AUTOSAR XML (schema 00048)
package /AUTOLIV/SoftwareComponents/DIA
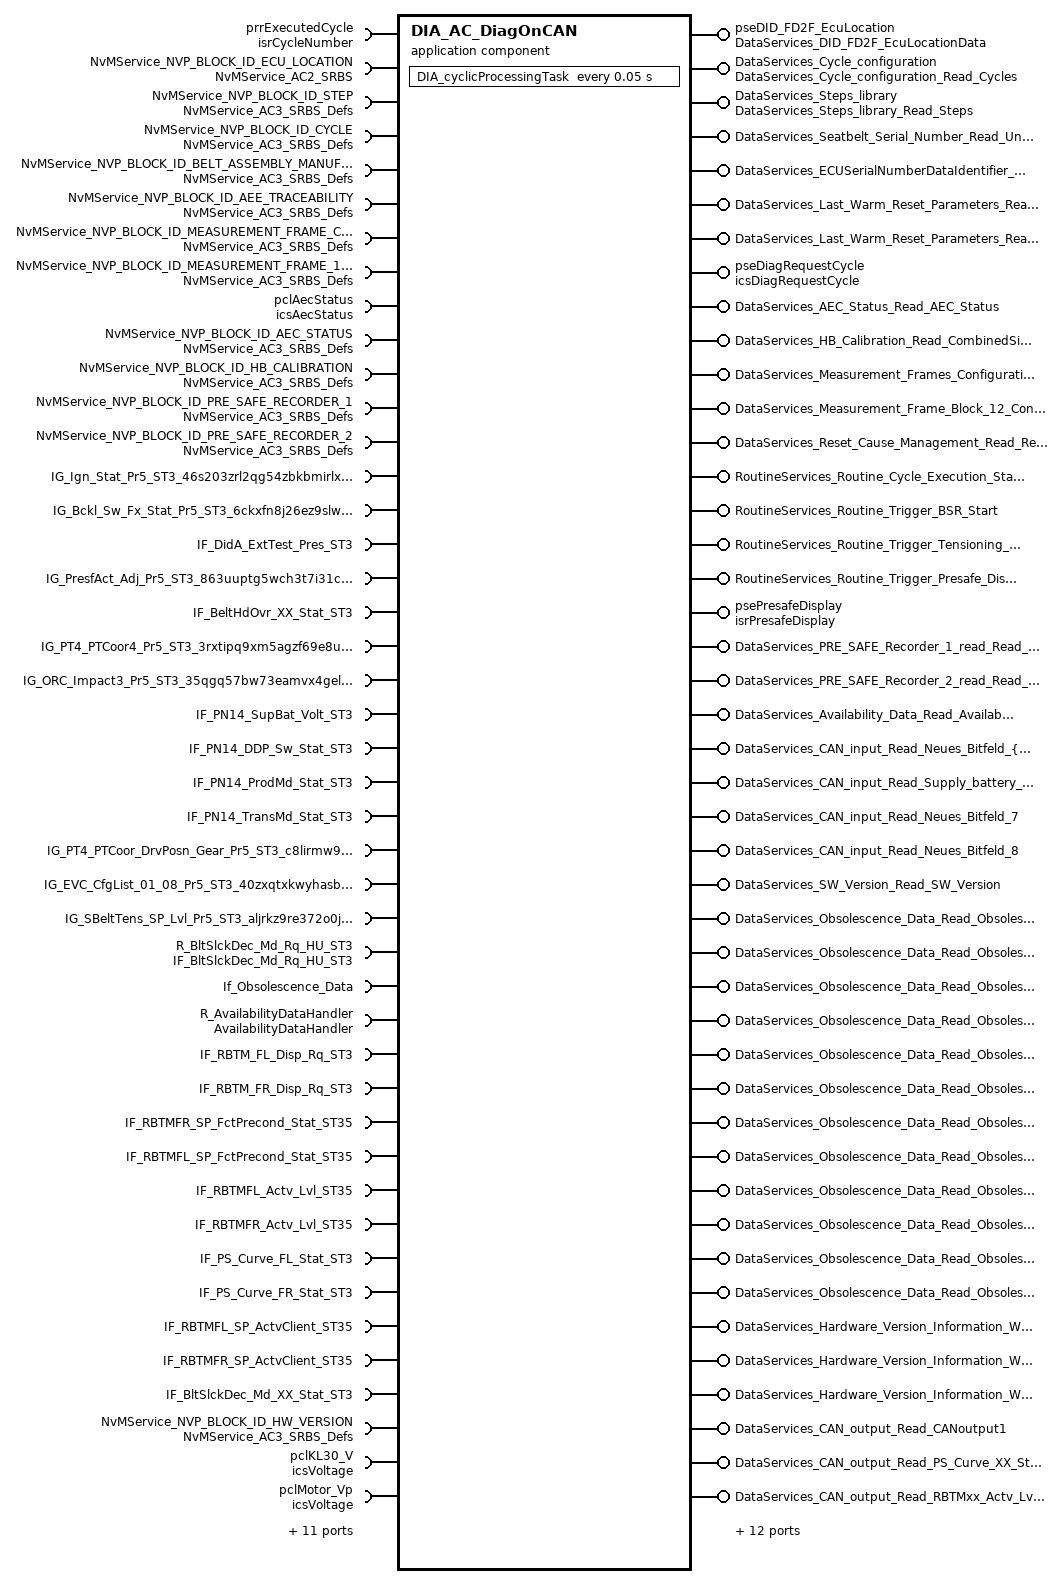
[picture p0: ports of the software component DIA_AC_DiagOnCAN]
  application sw component type DIA_AC_DiagOnCAN
    require port prrExecutedCycle: nonqueued-receiver-com-spec{data-element=u8CycleNumber, init-value=constant-reference=APPLINIT_KU8_CYCLE_NUMBER_NONE}, required-interface=isrCycleNumber
    provide port pseDID_FD2F_EcuLocation: provided-com-specs=[{operation=ReadData, queue-length=1}, {operation=WriteData, queue-length=1}], provided-interface=DataServices_DID_FD2F_EcuLocationData
    require port NvMService_NVP_BLOCK_ID_ECU_LOCATION: required-com-specs=[WriteBlock, SetRamBlockStatus, ReadBlock, GetErrorStatus], required-interface=NvMService_AC2_SRBS
    require port NvMService_NVP_BLOCK_ID_STEP: required-com-specs=[EraseBlock, InvalidateNvBlock, RestoreBlockDefaults, WriteBlock, ReadBlock, SetRamBlockStatus, GetErrorStatus], required-interface=NvMService_AC3_SRBS_Defs
    require port NvMService_NVP_BLOCK_ID_CYCLE: required-com-specs=[EraseBlock, InvalidateNvBlock, RestoreBlockDefaults, WriteBlock, ReadBlock, SetRamBlockStatus, GetErrorStatus], required-interface=NvMService_AC3_SRBS_Defs
    provide port DataServices_Cycle_configuration: provided-com-specs=[{operation=WriteData, queue-length=1}, {operation=ReadData, queue-length=1}], provided-interface=DataServices_Cycle_configuration_Read_Cycles
    provide port DataServices_Steps_library: provided-com-specs=[{operation=WriteData, queue-length=1}, {operation=ReadData, queue-length=1}], provided-interface=DataServices_Steps_library_Read_Steps
    require port NvMService_NVP_BLOCK_ID_BELT_ASSEMBLY_MANUF_DATE_AND_SN: required-com-specs=[EraseBlock, InvalidateNvBlock, RestoreBlockDefaults, WriteBlock, ReadBlock, SetRamBlockStatus, GetErrorStatus], required-interface=NvMService_AC3_SRBS_Defs
    require port NvMService_NVP_BLOCK_ID_AEE_TRACEABILITY: required-com-specs=[EraseBlock, InvalidateNvBlock, RestoreBlockDefaults, WriteBlock, ReadBlock, SetRamBlockStatus, GetErrorStatus], required-interface=NvMService_AC3_SRBS_Defs
    4 x provide port:
      DataServices_Seatbelt_Serial_Number_Read_Unique_Seatbelt_Serialnumber: provided-interface=DataServices_Seatbelt_Serial_Number_Read_Unique_Seatbelt_Serialnumber
        provided-com-specs:
          operation=WriteData, queue-length=1
          operation=ConditionCheckRead, queue-length=1
          operation=ReadData, queue-length=1
      DataServices_ECUSerialNumberDataIdentifier_Read_ECU_Serial_Number: provided-interface=DataServices_ECUSerialNumberDataIdentifier_Read_ECU_Serial_Number
        provided-com-specs:
          operation=ConditionCheckRead, queue-length=1
          operation=ReadDataLength, queue-length=1
          operation=ReadData, queue-length=1
      DataServices_Last_Warm_Reset_Parameters_Read_Last_Detected_Warm_Reset_Cause: provided-com-specs=[{operation=ConditionCheckRead, queue-length=1}, {operation=ReadData, queue-length=1}], provided-interface=DataServices_Last_Warm_Reset_Parameters_Read_Last_Detected_Warm_Reset_Cause
      DataServices_Last_Warm_Reset_Parameters_Read_Reset_Cause_Counter: provided-com-specs=[{operation=ConditionCheckRead, queue-length=1}, {operation=ReadData, queue-length=1}], provided-interface=DataServices_Last_Warm_Reset_Parameters_Read_Reset_Cause_Counter
    require port NvMService_NVP_BLOCK_ID_MEASUREMENT_FRAME_CONFIG: required-com-specs=[EraseBlock, InvalidateNvBlock, RestoreBlockDefaults, WriteBlock, ReadBlock, SetRamBlockStatus, GetErrorStatus], required-interface=NvMService_AC3_SRBS_Defs
    require port NvMService_NVP_BLOCK_ID_MEASUREMENT_FRAME_12_CONFIG: required-com-specs=[EraseBlock, InvalidateNvBlock, RestoreBlockDefaults, WriteBlock, ReadBlock, SetRamBlockStatus, GetErrorStatus], required-interface=NvMService_AC3_SRBS_Defs
    require port pclAecStatus: required-interface=icsAecStatus
      required-com-specs:
        SetAecEvent
        GetNumberOfImplementedAec
        GetAecStatus
        GetAecQualificationCount
        GetAecNvpBlockRecordingStatus
        GetAecGroupsStatus
        GetAecDeskillThrs
    6 x provide port:
      pseDiagRequestCycle: provided-com-specs=[{operation=GetDiagRequestCycle, queue-length=1}, {operation=ClearDiagRequestCycle, queue-length=1}], provided-interface=icsDiagRequestCycle
      DataServices_AEC_Status_Read_AEC_Status: provided-interface=DataServices_AEC_Status_Read_AEC_Status
        provided-com-specs:
          operation=ConditionCheckRead, queue-length=1
          operation=ReadDataLength, queue-length=1
          operation=ReadData, queue-length=1
      DataServices_HB_Calibration_Read_CombinedSignal: provided-interface=DataServices_HB_Calibration_Read_CombinedSignal
        provided-com-specs:
          operation=WriteData, queue-length=1
          operation=ConditionCheckRead, queue-length=1
          operation=ReadData, queue-length=1
      DataServices_Measurement_Frames_Configuration_Read_CombinedSignal: provided-interface=DataServices_Measurement_Frames_Configuration_Read_CombinedSignal
        provided-com-specs:
          operation=WriteData, queue-length=1
          operation=ConditionCheckRead, queue-length=1
          operation=ReadData, queue-length=1
      DataServices_Measurement_Frame_Block_12_Config_Read_CombinedSignal: provided-interface=DataServices_Measurement_Frame_Block_12_Config_Read_CombinedSignal
        provided-com-specs:
          operation=WriteData, queue-length=1
          operation=ConditionCheckRead, queue-length=1
          operation=ReadData, queue-length=1
      DataServices_Reset_Cause_Management_Read_Reset_Cause: provided-com-specs=[{operation=ConditionCheckRead, queue-length=1}, {operation=ReadData, queue-length=1}], provided-interface=DataServices_Reset_Cause_Management_Read_Reset_Cause
    require port NvMService_NVP_BLOCK_ID_AEC_STATUS: required-com-specs=[EraseBlock, InvalidateNvBlock, RestoreBlockDefaults, WriteBlock, ReadBlock, SetRamBlockStatus, GetErrorStatus], required-interface=NvMService_AC3_SRBS_Defs
    require port NvMService_NVP_BLOCK_ID_HB_CALIBRATION: required-com-specs=[EraseBlock, InvalidateNvBlock, RestoreBlockDefaults, WriteBlock, ReadBlock, SetRamBlockStatus, GetErrorStatus], required-interface=NvMService_AC3_SRBS_Defs
    8 x provide port:
      RoutineServices_Routine_Cycle_Execution_Start: provided-interface=RoutineServices_Routine_Cycle_Execution_Start
        provided-com-specs:
          operation=RequestResults, queue-length=1
          operation=Stop, queue-length=1
          operation=Start, queue-length=1
      RoutineServices_Routine_Trigger_BSR_Start: provided-interface=RoutineServices_Routine_Trigger_BSR_Start
        provided-com-specs:
          operation=RequestResults, queue-length=1
          operation=Stop, queue-length=1
          operation=Start, queue-length=1
      RoutineServices_Routine_Trigger_Tensioning_Cycle_Start: provided-interface=RoutineServices_Routine_Trigger_Tensioning_Cycle_Start
        provided-com-specs:
          operation=RequestResults, queue-length=1
          operation=Stop, queue-length=1
          operation=Start, queue-length=1
      RoutineServices_Routine_Trigger_Presafe_Display_Request_Start: provided-interface=RoutineServices_Routine_Trigger_Presafe_Display_Request_Start
        provided-com-specs:
          operation=RequestResults, queue-length=1
          operation=Stop, queue-length=1
          operation=Start, queue-length=1
      psePresafeDisplay: nonqueued-sender-com-spec{data-element=b8TriggerPreSafeRequestStatus, init-value=constant-reference=APPLINIT_KB8_BOOLEAN_FALSE}, provided-interface=isrPresafeDisplay
      DataServices_PRE_SAFE_Recorder_1_read_Read_CombinedDataElement: provided-interface=DataServices_PRE_SAFE_Recorder_1_read_Read_CombinedDataElement
        provided-com-specs:
          operation=WriteData, queue-length=1
          operation=ConditionCheckRead, queue-length=1
          operation=ReadDataLength, queue-length=1
          operation=ReadData, queue-length=1
      DataServices_PRE_SAFE_Recorder_2_read_Read_CombinedDataElement: provided-interface=DataServices_PRE_SAFE_Recorder_2_read_Read_CombinedDataElement
        provided-com-specs:
          operation=WriteData, queue-length=1
          operation=ConditionCheckRead, queue-length=1
          operation=ReadDataLength, queue-length=1
          operation=ReadData, queue-length=1
      DataServices_Availability_Data_Read_Availability_Data_PRE_SAFE_haptic_warning: provided-com-specs=[{operation=ConditionCheckRead, queue-length=1}, {operation=ReadData, queue-length=1}], provided-interface=DataServices_Availability_Data_Read_Availability_Data_PRE_SAFE_haptic_warning
    16 x require port:
      NvMService_NVP_BLOCK_ID_PRE_SAFE_RECORDER_1: required-com-specs=[EraseBlock, InvalidateNvBlock, RestoreBlockDefaults, WriteBlock, ReadBlock, SetRamBlockStatus, GetErrorStatus], required-interface=NvMService_AC3_SRBS_Defs
      NvMService_NVP_BLOCK_ID_PRE_SAFE_RECORDER_2: required-com-specs=[EraseBlock, InvalidateNvBlock, RestoreBlockDefaults, WriteBlock, ReadBlock, SetRamBlockStatus, GetErrorStatus], required-interface=NvMService_AC3_SRBS_Defs
      IG_Ign_Stat_Pr5_ST3_46s203zrl2qg54zbkbmirlx2b: nonqueued-receiver-com-spec{data-element=Ign_Stat_Pr5_ST3, filter=data-filter-type=ALWAYS, init-value=constant-reference=XDIS_8ptnmozvvqneybwnb1dteqblf}, required-interface=IG_Ign_Stat_Pr5_ST3_46s203zrl2qg54zbkbmirlx2b
      IG_Bckl_Sw_Fx_Stat_Pr5_ST3_6ckxfn8j26ez9slws8s7zuact: nonqueued-receiver-com-spec{data-element=Bckl_Sw_Fx_Stat_Pr5_ST3, filter=data-filter-type=ALWAYS, init-value=constant-reference=XDIS_by5k2ulzqy4hav7734lki195k}, required-interface=IG_Bckl_Sw_Fx_Stat_Pr5_ST3_6ckxfn8j26ez9slws8s7zuact
      IF_DidA_ExtTest_Pres_ST3: nonqueued-receiver-com-spec{data-element=DidA_ExtTest_Pres_ST3, filter=data-filter-type=ALWAYS, init-value=constant-reference=XDIS_f4mtuwvd3r353o80f6rps7w7}, required-interface=IF_DidA_ExtTest_Pres_ST3
      IG_PresfAct_Adj_Pr5_ST3_863uuptg5wch3t7i31c8crpa2: nonqueued-receiver-com-spec{data-element=PresfAct_Adj_Pr5_ST3, filter=data-filter-type=ALWAYS, init-value=constant-reference=XDIS_1lex2znuqx5p6s5yy1dyffpdg}, required-interface=IG_PresfAct_Adj_Pr5_ST3_863uuptg5wch3t7i31c8crpa2
      IF_BeltHdOvr_XX_Stat_ST3: nonqueued-receiver-com-spec{data-element=BeltHdOvr_XX_Stat_ST3, filter=data-filter-type=ALWAYS, init-value=constant-reference=XDIS_9pu33xhskzhvc3a6idhpuk7uh}, required-interface=IF_BeltHdOvr_XX_Stat_ST3
      IG_PT4_PTCoor4_Pr5_ST3_3rxtipq9xm5agzf69e8usehmj: nonqueued-receiver-com-spec{data-element=PT4_PTCoor4_Pr5_ST3, filter=data-filter-type=ALWAYS, init-value=constant-reference=XDIS_9h6oqehaueepowg2tijus0mir}, required-interface=IG_PT4_PTCoor4_Pr5_ST3_3rxtipq9xm5agzf69e8usehmj
      IG_ORC_Impact3_Pr5_ST3_35qgq57bw73eamvx4gelk7iiv: nonqueued-receiver-com-spec{data-element=ORC_Impact3_Pr5_ST3, filter=data-filter-type=ALWAYS, init-value=constant-reference=XDIS_7frhrem3wt9j2oidbosrki6rx}, required-interface=IG_ORC_Impact3_Pr5_ST3_35qgq57bw73eamvx4gelk7iiv
      IF_PN14_SupBat_Volt_ST3: nonqueued-receiver-com-spec{data-element=PN14_SupBat_Volt_ST3, filter=data-filter-type=ALWAYS, init-value=constant-reference=XDIS_9jzhpgyeg4j2n16k3jmfeesjo}, required-interface=IF_PN14_SupBat_Volt_ST3
      IF_PN14_DDP_Sw_Stat_ST3: nonqueued-receiver-com-spec{data-element=PN14_DDP_Sw_Stat_ST3, filter=data-filter-type=ALWAYS, init-value=constant-reference=XDIS_c8apwmaohcx1gxigvciebloy2}, required-interface=IF_PN14_DDP_Sw_Stat_ST3
      IF_PN14_ProdMd_Stat_ST3: nonqueued-receiver-com-spec{data-element=PN14_ProdMd_Stat_ST3, filter=data-filter-type=ALWAYS, init-value=constant-reference=XDIS_4um78o9kgep1cp3dhn51ycc2o}, required-interface=IF_PN14_ProdMd_Stat_ST3
      IF_PN14_TransMd_Stat_ST3: nonqueued-receiver-com-spec{data-element=PN14_TransMd_Stat_ST3, filter=data-filter-type=ALWAYS, init-value=constant-reference=XDIS_18rb2bxx4r5d75figzrcw50gp}, required-interface=IF_PN14_TransMd_Stat_ST3
      IG_PT4_PTCoor_DrvPosn_Gear_Pr5_ST3_c8lirmw9wm5odas0h648yyd4w: nonqueued-receiver-com-spec{data-element=PT4_PTCoor_DrvPosn_Gear_Pr5_ST3, filter=data-filter-type=ALWAYS, init-value=constant-reference=XDIS_8ocy3iwo1ditemd6qwphg7b7i}, required-interface=IG_PT4_PTCoor_DrvPosn_Gear_Pr5_ST3_c8lirmw9wm5odas0h648yyd4w
      IG_EVC_CfgList_01_08_Pr5_ST3_40zxqtxkwyhasb66rr3qexjf2: nonqueued-receiver-com-spec{data-element=EVC_CfgList_01_08_Pr5_ST3, filter=data-filter-type=ALWAYS, init-value=constant-reference=XDIS_7tqm5jy9oba0thvws62i3l28n}, required-interface=IG_EVC_CfgList_01_08_Pr5_ST3_40zxqtxkwyhasb66rr3qexjf2
      IG_SBeltTens_SP_Lvl_Pr5_ST3_aljrkz9re372o0jtum2i5lh8w: nonqueued-receiver-com-spec{data-element=SBeltTens_SP_Lvl_Pr5_ST3, filter=data-filter-type=ALWAYS, init-value=constant-reference=XDIS_4wiqeqoz18rz4k73xcp12oii1}, required-interface=IG_SBeltTens_SP_Lvl_Pr5_ST3_aljrkz9re372o0jtum2i5lh8w
    10 x provide port, all with provided-com-specs=[{operation=ConditionCheckRead, queue-length=1}, {operation=ReadData, queue-length=1}]:
      DataServices_CAN_input_Read_Neues_Bitfeld_{1..6}: provided-interface=DataServices_CAN_input_Read_Neues_Bitfeld_{1..6}
      DataServices_CAN_input_Read_Supply_battery_voltage: provided-interface=DataServices_CAN_input_Read_Supply_battery_voltage
      DataServices_CAN_input_Read_Neues_Bitfeld_7: provided-interface=DataServices_CAN_input_Read_Neues_Bitfeld_7
      DataServices_CAN_input_Read_Neues_Bitfeld_8: provided-interface=DataServices_CAN_input_Read_Neues_Bitfeld_8
      DataServices_SW_Version_Read_SW_Version: provided-interface=DataServices_SW_Version_Read_SW_Version
    require port R_BltSlckDec_Md_Rq_HU_ST3: nonqueued-receiver-com-spec{data-element=BltSlckDec_Md_Rq_HU_ST3, filter=data-filter-type=ALWAYS, init-value=constant-reference=XDIS_1vei4uht6zuq0e57z2qtds6y7}, required-interface=IF_BltSlckDec_Md_Rq_HU_ST3
    12 x provide port, all with provided-com-specs=[{operation=ConditionCheckRead, queue-length=1}, {operation=ReadData, queue-length=1}]:
      DataServices_Obsolescence_Data_Read_Obsolescence_Data_BSR_Current_Value: provided-interface=DataServices_Obsolescence_Data_Read_Obsolescence_Data_BSR_Current_Value
      DataServices_Obsolescence_Data_Read_Obsolescence_Data_BSR_Threshold_Green_to_Yellow: provided-interface=DataServices_Obsolescence_Data_Read_Obsolescence_Data_BSR_Threshold_Green_to_Yellow
      DataServices_Obsolescence_Data_Read_Obsolescence_Data_BSR_Threshold_Yellow_to_Red: provided-interface=DataServices_Obsolescence_Data_Read_Obsolescence_Data_BSR_Threshold_Yellow_to_Red
      DataServices_Obsolescence_Data_Read_Obsolescence_Data_haptic_Warning_Current_Value: provided-interface=DataServices_Obsolescence_Data_Read_Obsolescence_Data_haptic_Warning_Current_Value
      DataServices_Obsolescence_Data_Read_Obsolescence_Data_haptic_Warning_Threshold_Green_to_Yellow: provided-interface=DataServices_Obsolescence_Data_Read_Obsolescence_Data_haptic_Warning_Threshold_Green_to_Yellow
      DataServices_Obsolescence_Data_Read_Obsolescence_Data_haptic_Warning_Threshold_Yellow_to_Red: provided-interface=DataServices_Obsolescence_Data_Read_Obsolescence_Data_haptic_Warning_Threshold_Yellow_to_Red
      DataServices_Obsolescence_Data_Read_Obsolescence_Data_PRE_CRASH_Current_Value: provided-interface=DataServices_Obsolescence_Data_Read_Obsolescence_Data_PRE_CRASH_Current_Value
      DataServices_Obsolescence_Data_Read_Obsolescence_Data_PRE_CRASH_Threshold_Green_to_Yellow: provided-interface=DataServices_Obsolescence_Data_Read_Obsolescence_Data_PRE_CRASH_Threshold_Green_to_Yellow
      DataServices_Obsolescence_Data_Read_Obsolescence_Data_PRE_CRASH_Threshold_Yellow_to_Red: provided-interface=DataServices_Obsolescence_Data_Read_Obsolescence_Data_PRE_CRASH_Threshold_Yellow_to_Red
      DataServices_Obsolescence_Data_Read_Obsolescence_Data_PRE_SAFE_Lvl_4_5_Current_Value: provided-interface=DataServices_Obsolescence_Data_Read_Obsolescence_Data_PRE_SAFE_Lvl_4_5_Current_Value
      DataServices_Obsolescence_Data_Read_Obsolescence_Data_PRE_SAFE_Lvl_4_5_Threshold_Green_to_Yellow: provided-interface=DataServices_Obsolescence_Data_Read_Obsolescence_Data_PRE_SAFE_Lvl_4_5_Threshold_Green_to_Yellow
      DataServices_Obsolescence_Data_Read_Obsolescence_Data_PRE_SAFE_Lvl_4_5_Threshold_Yellow_to_Red: provided-interface=DataServices_Obsolescence_Data_Read_Obsolescence_Data_PRE_SAFE_Lvl_4_5_Threshold_Yellow_to_Red
    require port If_Obsolescence_Data: required-com-specs=[Write_Data, Get_Data], required-interface=If_Obsolescence_Data
    require port R_AvailabilityDataHandler: nonqueued-receiver-com-spec{data-element=AvailabilityDataCategory, filter=data-filter-type=ALWAYS, init-value=0}, required-interface=AvailabilityDataHandler
    provide port DataServices_Hardware_Version_Information_Write_HW_year: server-com-spec{operation=WriteData, queue-length=1}, provided-interface=DataServices_Hardware_Version_Information_Write_HW_year
    provide port DataServices_Hardware_Version_Information_Write_HW_week: server-com-spec{operation=WriteData, queue-length=1}, provided-interface=DataServices_Hardware_Version_Information_Write_HW_week
    provide port DataServices_Hardware_Version_Information_Write_HW_patch_level: server-com-spec{operation=WriteData, queue-length=1}, provided-interface=DataServices_Hardware_Version_Information_Write_HW_patch_level
    11 x require port:
      IF_RBTM_FL_Disp_Rq_ST3: nonqueued-receiver-com-spec{data-element=RBTM_FL_Disp_Rq_ST3, filter=data-filter-type=ALWAYS}, required-interface=IF_RBTM_FL_Disp_Rq_ST3
      IF_RBTM_FR_Disp_Rq_ST3: nonqueued-receiver-com-spec{data-element=RBTM_FR_Disp_Rq_ST3, filter=data-filter-type=ALWAYS}, required-interface=IF_RBTM_FR_Disp_Rq_ST3
      IF_RBTMFR_SP_FctPrecond_Stat_ST35: nonqueued-receiver-com-spec{data-element=RBTMFR_SP_FctPrecond_Stat_ST35, filter=data-filter-type=ALWAYS}, required-interface=IF_RBTMFR_SP_FctPrecond_Stat_ST35
      IF_RBTMFL_SP_FctPrecond_Stat_ST35: nonqueued-receiver-com-spec{data-element=RBTMFL_SP_FctPrecond_Stat_ST35, filter=data-filter-type=ALWAYS}, required-interface=IF_RBTMFL_SP_FctPrecond_Stat_ST35
      IF_RBTMFL_Actv_Lvl_ST35: nonqueued-receiver-com-spec{data-element=RBTMFL_Actv_Lvl_ST35, filter=data-filter-type=ALWAYS}, required-interface=IF_RBTMFL_Actv_Lvl_ST35
      IF_RBTMFR_Actv_Lvl_ST35: nonqueued-receiver-com-spec{data-element=RBTMFR_Actv_Lvl_ST35, filter=data-filter-type=ALWAYS}, required-interface=IF_RBTMFR_Actv_Lvl_ST35
      IF_PS_Curve_FL_Stat_ST3: nonqueued-receiver-com-spec{data-element=PS_Curve_FL_Stat_ST3, filter=data-filter-type=ALWAYS}, required-interface=IF_PS_Curve_FL_Stat_ST3
      IF_PS_Curve_FR_Stat_ST3: nonqueued-receiver-com-spec{data-element=PS_Curve_FR_Stat_ST3, filter=data-filter-type=ALWAYS}, required-interface=IF_PS_Curve_FR_Stat_ST3
      IF_RBTMFL_SP_ActvClient_ST35: nonqueued-receiver-com-spec{data-element=RBTMFL_SP_ActvClient_ST35, filter=data-filter-type=ALWAYS}, required-interface=IF_RBTMFL_SP_ActvClient_ST35
      IF_RBTMFR_SP_ActvClient_ST35: nonqueued-receiver-com-spec{data-element=RBTMFR_SP_ActvClient_ST35, filter=data-filter-type=ALWAYS}, required-interface=IF_RBTMFR_SP_ActvClient_ST35
      IF_BltSlckDec_Md_XX_Stat_ST3: nonqueued-receiver-com-spec{data-element=BltSlckDec_Md_XX_Stat_ST3, filter=data-filter-type=ALWAYS, init-value=3}, required-interface=IF_BltSlckDec_Md_XX_Stat_ST3
    5 x provide port, all with provided-com-specs=[{operation=ConditionCheckRead, queue-length=1}, {operation=ReadData, queue-length=1}]:
      DataServices_CAN_output_Read_CANoutput1: provided-interface=DataServices_CAN_output_Read_CANoutput1
      DataServices_CAN_output_Read_PS_Curve_XX_Stat_ST3: provided-interface=DataServices_CAN_output_Read_PS_Curve_XX_Stat_ST3
      DataServices_CAN_output_Read_RBTMxx_Actv_Lvl_ST35: provided-interface=DataServices_CAN_output_Read_RBTMxx_Actv_Lvl_ST35
      DataServices_CAN_output_Read_RBTMxx_SP_ActvClient_ST35: provided-interface=DataServices_CAN_output_Read_RBTMxx_SP_ActvClient_ST35
      DataServices_CAN_output_Read_RBTMxx_SP_FctPrecond_Stat_ST35: provided-interface=DataServices_CAN_output_Read_RBTMxx_SP_FctPrecond_Stat_ST35
    require port NvMService_NVP_BLOCK_ID_HW_VERSION: required-com-specs=[EraseBlock, InvalidateNvBlock, RestoreBlockDefaults, WriteBlock, ReadBlock, SetRamBlockStatus, GetErrorStatus], required-interface=NvMService_AC3_SRBS_Defs
    4 x provide port, all with provided-com-specs=[{operation=ConditionCheckRead, queue-length=1}, {operation=ReadData, queue-length=1}]:
      DataServices_Internal_ECU_information_Read_ECU_Temperature: provided-interface=DataServices_Internal_ECU_information_Read_ECU_Temperature
      DataServices_Internal_ECU_information_Read_MOTOR_Current: provided-interface=DataServices_Internal_ECU_information_Read_MOTOR_Current
      DataServices_HW_input_Read_Voltage_KL30t: provided-interface=DataServices_HW_input_Read_Voltage_KL30t
      DataServices_HW_input_Read_Voltage_Motor: provided-interface=DataServices_HW_input_Read_Voltage_Motor
    4 x require port:
      pclKL30_V: required-com-specs=[Get_2ms, Get_20ms, Get_10ms, Get_100ms, Get], required-interface=icsVoltage
      pclMotor_Vp: required-com-specs=[Get_2ms, Get_20ms, Get_10ms, Get_100ms, Get], required-interface=icsVoltage
      pclMotor_I: required-com-specs=[Get_mA, Get_LSB, Get_A, ConvertCurrent_mAtoLSB], required-interface=icsCurrent
      pclECUT_T: required-com-specs=[Init, GetFiltered_deg, GetFiltered], required-interface=icsTemperature
    provide port DataServices_Internal_ECU_information_Read_Autosar_System_State_EcuM_State: provided-com-specs=[{operation=ConditionCheckRead, queue-length=1}, {operation=ReadData, queue-length=1}], provided-interface=DataServices_Internal_ECU_information_Read_Autosar_System_State_EcuM_State
    require port EcuM_CurrentMode: mode-switch-receiver-com-spec=currentMode, required-interface=EcuM_CurrentMode
    provide port DataServices_ECU_serial_number_Read_PCBA_Programmed_Part_number: provided-interface=DataServices_ECU_serial_number_Read_PCBA_Programmed_Part_number
      provided-com-specs:
        operation=WriteData, queue-length=1
        operation=ConditionCheckRead, queue-length=1
        operation=ReadData, queue-length=1
    provide port DataServices_ECU_serial_number_Read_ECU_traceability_number: provided-interface=DataServices_ECU_serial_number_Read_ECU_traceability_number
      provided-com-specs:
        operation=WriteData, queue-length=1
        operation=ConditionCheckRead, queue-length=1
        operation=ReadData, queue-length=1
    require port icsResetCause: required-com-specs=[GetResetCause, DetermineResetCause, ConfirmResetCause], required-interface=icsResetCause
    require port DcmDiagnosticSessionControl: mode-switch-receiver-com-spec=DcmDiagnosticSessionControl, required-interface=DcmDiagnosticSessionControl
    require port IF_VehSpd_Disp_ST3: nonqueued-receiver-com-spec{data-element=VehSpd_Disp_ST3, filter=data-filter-type=ALWAYS, init-value=0}, required-interface=IF_VehSpd_Disp_ST3
    provide port RoutineServices_Routine_Check_Reprogramming_Preconditions_Start: server-com-spec{operation=Start, queue-length=1}, provided-interface=RoutineServices_Routine_Check_Reprogramming_Preconditions_Start
    require port prrExtTestPres: required-interface=isrExtTestPres
      required-com-specs:
        data-element=b8ExtTesterPresent, filter=data-filter-type=ALWAYS
        data-element=b8DTCConfirmed, filter=data-filter-type=ALWAYS
    require port prrDTCConfirmed: required-interface=isrExtTestPres
      required-com-specs:
        data-element=b8DTCConfirmed, filter=data-filter-type=ALWAYS, init-value=constant-reference=APPLINIT_KB8_BOOLEAN_FALSE
        data-element=b8ExtTesterPresent, filter=data-filter-type=ALWAYS, init-value=constant-reference=APPLINIT_KB8_BOOLEAN_FALSE
    provide port DataServices_Temperature_Sensor_Calibration_Point_Read_Offset_Point: provided-interface=DataServices_Temperature_Sensor_Calibration_Point_Read_Offset_Point
      provided-com-specs:
        operation=WriteData, queue-length=1
        operation=ConditionCheckRead, queue-length=1
        operation=ReadData, queue-length=1
    require port NvMService_NVP_BLOCK_TEMP_SENSOR_TABLE: required-com-specs=[EraseBlock, InvalidateNvBlock, RestoreBlockDefaults, WriteBlock, ReadBlock, SetRamBlockStatus, GetErrorStatus], required-interface=NvMService_AC3_SRBS_Defs
    provide port DataServices_Velocity_PI_Regulation_Coefficient_Read_Input_Velocity_Coefficient: provided-interface=DataServices_Velocity_PI_Regulation_Coefficient_Read_Input_Velocity_Coefficient
      provided-com-specs:
        operation=WriteData, queue-length=1
        operation=ConditionCheckRead, queue-length=1
        operation=ReadData, queue-length=1
    require port NvMService_NVP_BLOCK_ID_VELOCITY_PID_PARAM: required-com-specs=[EraseBlock, InvalidateNvBlock, RestoreBlockDefaults, WriteBlock, ReadBlock, SetRamBlockStatus, GetErrorStatus], required-interface=NvMService_AC3_SRBS_Defs
    require port NvMService_NVP_BLOCK_ID_PCBA_PPN: required-com-specs=[EraseBlock, InvalidateNvBlock, RestoreBlockDefaults, WriteBlock, ReadBlock, SetRamBlockStatus, GetErrorStatus], required-interface=NvMService_AC3_SRBS_Defs
    behavior DIA_IB_DiagOnCAN: data-type-mapping=[DataTypeMappingSet_PP4G, DataTypeMappings_DEV]
      41 x operation invoked event:
        oie_pseDID_FD2F_EcuLocation_ReadData: start-on-event=DIA_runDidFD2F_EcuLocationRead, operation=pseDID_FD2F_EcuLocation.ReadData
        oie_pseDID_FD2F_EcuLocation_WriteData: start-on-event=DIA_runDidFD2F_EcuLocationWrite, operation=pseDID_FD2F_EcuLocation.WriteData
        OIT_DIA_runDidFD2A_StepsLibraryWrite_DataServices_Steps_library_WriteData: start-on-event=DIA_runDidFD2A_StepsLibraryWrite, operation=DataServices_Steps_library.WriteData
        OIT_DIA_runDidFD2A_StepsLibraryRead_DataServices_Steps_library_ReadData: start-on-event=DIA_runDidFD2A_StepsLibraryRead, operation=DataServices_Steps_library.ReadData
        OIT_DIA_runDidFD10_CycleConfigurationRead_DataServices_Cycle_configuration_ReadData: start-on-event=DIA_runDidFD10_CycleConfigurationRead, operation=DataServices_Cycle_configuration.ReadData
        OIT_DIA_runDidFD10_CycleConfigurationWrite_DataServices_Cycle_configuration_WriteData: start-on-event=DIA_runDidFD10_CycleConfigurationWrite, operation=DataServices_Cycle_configuration.WriteData
        OIT_DIA_runDid0340_UniqueSeatbeltSerialNumberConditionCheckRead_DataServices_Seatbelt_Serial_Number_Read_Unique_SeatbeltFBF9722C: start-on-event=DIA_runDid0340_UniqueSeatbeltSerialNumberConditionCheckRead, operation=DataServices_Seatbelt_Serial_Number_Read_Unique_Seatbelt_Serialnumber.ConditionCheckRead
        OIT_DIA_runDid0340_UniqueSeatbeltSerialNumberRead_DataServices_Seatbelt_Serial_Number_Read_Unique_Seatbelt_Serialnumber_ReadData: start-on-event=DIA_runDid0340_UniqueSeatbeltSerialNumberRead, operation=DataServices_Seatbelt_Serial_Number_Read_Unique_Seatbelt_Serialnumber.ReadData
        OIT_DIA_runDid0340_UniqueSeatbeltSerialNumberWrite_DataServices_Seatbelt_Serial_Number_Read_Unique_Seatbelt_Serialnumber2E96F11D: start-on-event=DIA_runDid0340_UniqueSeatbeltSerialNumberWrite, operation=DataServices_Seatbelt_Serial_Number_Read_Unique_Seatbelt_Serialnumber.WriteData
        OIT_DIA_runDidF18C_EcuSerialNumberConditionCheckRead_DataServices_ECUSerialNumberDataIdentifier_Read_ECU_Serial_Number_C2B16EED8: start-on-event=DIA_runDidF18C_EcuSerialNumberConditionCheckRead, operation=DataServices_ECUSerialNumberDataIdentifier_Read_ECU_Serial_Number.ConditionCheckRead
        OIT_DIA_runDidF18C_EcuSerialNumberRead_DataServices_ECUSerialNumberDataIdentifier_Read_ECU_Serial_Number_ReadData: start-on-event=DIA_runDidF18C_EcuSerialNumberRead, operation=DataServices_ECUSerialNumberDataIdentifier_Read_ECU_Serial_Number.ReadData
        OIT_DIA_runDidF18C_EcuSerialNumberReadDataLength_DataServices_ECUSerialNumberDataIdentifier_Read_ECU_Serial_Number_ReadDB340CCB8: start-on-event=DIA_runDidF18C_EcuSerialNumberReadDataLength, operation=DataServices_ECUSerialNumberDataIdentifier_Read_ECU_Serial_Number.ReadDataLength
        OIT_DIA_runDidFD09_LastWarmResetConditionCheckRead_ResetCauseCounter_DataServices_Last_Warm_Reset_Parameters_Read_Reset_52475C36: start-on-event=DIA_runDidFD09_LastWarmResetConditionCheckRead_ResetCauseCounter, operation=DataServices_Last_Warm_Reset_Parameters_Read_Reset_Cause_Counter.ConditionCheckRead
        OIT_DIA_runDidFD09_LastWarmReseConditionChecktRead_LastDetectedWarmResetCause_DataServices_Last_Warm_Reset_Parameters_Re84DF461B: start-on-event=DIA_runDidFD09_LastWarmReseConditionChecktRead_LastDetectedWarmResetCause, operation=DataServices_Last_Warm_Reset_Parameters_Read_Last_Detected_Warm_Reset_Cause.ConditionCheckRead
        OIT_DIA_runDidFD09_LastWarmResetRead_LastDetectedWarmResetCause_DataServices_Last_Warm_Reset_Parameters_Read_Last_DetectB87375AF: start-on-event=DIA_runDidFD09_LastWarmResetRead_LastDetectedWarmResetCause, operation=DataServices_Last_Warm_Reset_Parameters_Read_Last_Detected_Warm_Reset_Cause.ReadData
        OIT_DIA_runDidFD09_LastWarmResetRead_ResetCauseCounter_DataServices_Last_Warm_Reset_Parameters_Read_Reset_Cause_Counter_ReadData: start-on-event=DIA_runDidFD09_LastWarmResetRead_ResetCauseCounter, operation=DataServices_Last_Warm_Reset_Parameters_Read_Reset_Cause_Counter.ReadData
        OIT_DIA_runGetDiagRequestCycle_pseDiagRequestCycle_GetDiagRequestCycle: start-on-event=DIA_runGetDiagRequestCycle, operation=pseDiagRequestCycle.GetDiagRequestCycle
        OIT_DIA_runClearDiagRequestCycle_pseDiagRequestCycle_ClearDiagRequestCycle: start-on-event=DIA_runClearDiagRequestCycle, operation=pseDiagRequestCycle.ClearDiagRequestCycle
        OIT_DIA_runDidFEFF_MeasuruementFrameConfigurationRead_DataServices_Measurement_Frames_Configuration_Read_CombinedSignal_ReadData: start-on-event=DIA_runDidFEFF_MeasuruementFrameConfigurationRead, operation=DataServices_Measurement_Frames_Configuration_Read_CombinedSignal.ReadData
        OIT_DIA_runDidFEFF_MeasuruementFrameConfigurationWrite_DataServices_Measurement_Frames_Configuration_Read_CombinedSignal10D7FD8D: start-on-event=DIA_runDidFEFF_MeasuruementFrameConfigurationWrite, operation=DataServices_Measurement_Frames_Configuration_Read_CombinedSignal.WriteData
        OIT_DIA_runDidFEFF_MeasuruementFrameConfigurationConditionCheckRead_DataServices_Measurement_Frames_Configuration_Read_C87A3B1E5: start-on-event=DIA_runDidFEFF_MeasuruementFrameConfigurationConditionCheckRead, operation=DataServices_Measurement_Frames_Configuration_Read_CombinedSignal.ConditionCheckRead
        OIT_DIA_runDidFD31_HBCalibrationRead_DataServices_HB_Calibration_Read_CombinedSignal_ReadData: start-on-event=DIA_runDidFD31_HBCalibrationRead, operation=DataServices_HB_Calibration_Read_CombinedSignal.ReadData
        OIT_DIA_runDidFD31_HBCalibrationWrite_DataServices_HB_Calibration_Read_CombinedSignal_WriteData: start-on-event=DIA_runDidFD31_HBCalibrationWrite, operation=DataServices_HB_Calibration_Read_CombinedSignal.WriteData
        OIT_DIA_runDidFD31_HBCalibrationWriteConditionCheckRead_DataServices_HB_Calibration_Read_CombinedSignal_ConditionCheckRead: start-on-event=DIA_runDidFD31_HBCalibrationWriteConditionCheckRead, operation=DataServices_HB_Calibration_Read_CombinedSignal.ConditionCheckRead
        OIT_DIA_runDidFDFF_MeasurementFrameBlock12ConfigConditionCheckRead_DataServices_Measurement_Frame_Block_12_Config_Read_C10E2BBE6: start-on-event=DIA_runDidFDFF_MeasurementFrameBlock12ConfigConditionCheckRead, operation=DataServices_Measurement_Frame_Block_12_Config_Read_CombinedSignal.ConditionCheckRead
        OIT_DIA_runDidFDFF_MeasurementFrameBlock12ConfigRead_DataServices_Measurement_Frame_Block_12_Config_Read_CombinedSignal_ReadData: start-on-event=DIA_runDidFDFF_MeasurementFrameBlock12ConfigRead, operation=DataServices_Measurement_Frame_Block_12_Config_Read_CombinedSignal.ReadData
        OIT_DIA_runDidFDFF_MeasurementFrameBlock12ConfigWrite_DataServices_Measurement_Frame_Block_12_Config_Read_CombinedSignalF9DD0DE8: start-on-event=DIA_runDidFDFF_MeasurementFrameBlock12ConfigWrite, operation=DataServices_Measurement_Frame_Block_12_Config_Read_CombinedSignal.WriteData
        OIT_DIA_runDidFE00_AECStatusRead_DataServices_AEC_Status_Read_AEC_Status_ReadData: start-on-event=DIA_runDidFE00_AECStatusRead, operation=DataServices_AEC_Status_Read_AEC_Status.ReadData
        OIT_DIA_runDidFE00_AECStatusWrite_DataServices_AEC_Status_Read_AEC_Status_ReadDataLength: start-on-event=DIA_runDidFE00_AECStatusReadDataLength, operation=DataServices_AEC_Status_Read_AEC_Status.ReadDataLength
        OIT_DIA_runDidFE00_AECStatusConditionCheckRead_DataServices_AEC_Status_Read_AEC_Status_ConditionCheckRead: start-on-event=DIA_runDidFE00_AECStatusConditionCheckRead, operation=DataServices_AEC_Status_Read_AEC_Status.ConditionCheckRead
        OIT_DIA_runDidFD80_ResetCauseManagementRead_DataServices_Reset_Cause_Management_Read_Reset_Cause_ReadData: start-on-event=DIA_runDidFD08_ResetCauseManagementRead, operation=DataServices_Reset_Cause_Management_Read_Reset_Cause.ReadData
        OIT_DIA_runDidFD80_ResetCauseManagementConditionCheckRead_DataServices_Reset_Cause_Management_Read_Reset_Cause_Condition49FA4C2F: start-on-event=DIA_runDidFD08_ResetCauseManagementConditionCheckRead, operation=DataServices_Reset_Cause_Management_Read_Reset_Cause.ConditionCheckRead
        OIT_DIA_runRidF703_CycleExecutionRequestResults_RoutineServices_Routine_Cycle_Execution_Start_1_RequestResults: start-on-event=DIA_runRidF703_CycleExecutionRequestResults, operation=RoutineServices_Routine_Cycle_Execution_Start.RequestResults
        OIT_DIA_runRidF703_CycleExecutionStart_RoutineServices_Routine_Cycle_Execution_Start_1_Start: start-on-event=DIA_runRidF703_CycleExecutionStart, operation=RoutineServices_Routine_Cycle_Execution_Start.Start
        OIT_DIA_runRidF703_CycleExecutionStop_RoutineServices_Routine_Cycle_Execution_Start_1_Stop: start-on-event=DIA_runRidF703_CycleExecutionStop, operation=RoutineServices_Routine_Cycle_Execution_Start.Stop
        OIT_DIA_runRid0329_TriggerBSRRequestResults_RoutineServices_Routine_Trigger_BSR_Start_RequestResults: start-on-event=DIA_runRid0329_TriggerBSRRequestResults, operation=RoutineServices_Routine_Trigger_BSR_Start.RequestResults
        OIT_DIA_runRid0329_TriggerBSRStart_RoutineServices_Routine_Trigger_BSR_Start_Start: start-on-event=DIA_runRid0329_TriggerBSRStart, operation=RoutineServices_Routine_Trigger_BSR_Start.Start
        OIT_DIA_runRid0329_TriggerBSRStop_RoutineServices_Routine_Trigger_BSR_Start_Stop: start-on-event=DIA_runRid0329_TriggerBSRStop, operation=RoutineServices_Routine_Trigger_BSR_Start.Stop
        OIT_DIA_runRid0330_TriggerTensioningCycleRequestResults_RoutineServices_Routine_Trigger_Tensioning_Cycle_Start_RequestResults: start-on-event=DIA_runRid0330_TriggerTensioningCycleRequestResults, operation=RoutineServices_Routine_Trigger_Tensioning_Cycle_Start.RequestResults
        OIT_DIA_runRid0330_TriggerTensioningCycleStart_RoutineServices_Routine_Trigger_Tensioning_Cycle_Start_Start: start-on-event=DIA_runRid0330_TriggerTensioningCycleStart, operation=RoutineServices_Routine_Trigger_Tensioning_Cycle_Start.Start
        OIT_DIA_runRid0330_TriggerTensioningCycleStop_RoutineServices_Routine_Trigger_Tensioning_Cycle_Start_Stop: start-on-event=DIA_runRid0330_TriggerTensioningCycleStop, operation=RoutineServices_Routine_Trigger_Tensioning_Cycle_Start.Stop
      timing event TMT_DIA_cyclicProcessingTask: start-on-event=DIA_cyclicProcessingTask, period=0.05
      93 x operation invoked event:
        OIT_DIA_runRid0302_TriggerPresafeDisplayRequestRequestResults_RoutineServices_Routine_Trigger_Presafe_Display_Request_St13F6A6F9: start-on-event=DIA_runRid0302_TriggerPresafeDisplayRequestRequestResults, operation=RoutineServices_Routine_Trigger_Presafe_Display_Request_Start.RequestResults
        OIT_DIA_runRid0302_TriggerPresafeDisplayRequestStart_RoutineServices_Routine_Trigger_Presafe_Display_Request_Start_Start: start-on-event=DIA_runRid0302_TriggerPresafeDisplayRequestStart, operation=RoutineServices_Routine_Trigger_Presafe_Display_Request_Start.Start
        OIT_DIA_runRid0302_TriggerPresafeDisplayRequestStop_RoutineServices_Routine_Trigger_Presafe_Display_Request_Start_Stop: start-on-event=DIA_runRid0302_TriggerPresafeDisplayRequestStop, operation=RoutineServices_Routine_Trigger_Presafe_Display_Request_Start.Stop
        OIT_DIA_runDid0142_AvailabilityDataConditionsCheckRead_DataServices_Availability_Data_Read_Availability_Data_PRE_SAFE_haBB032224: start-on-event=DIA_runDid0142_AvailabilityDataConditionsCheckRead, operation=DataServices_Availability_Data_Read_Availability_Data_PRE_SAFE_haptic_warning.ConditionCheckRead
        OIT_DIA_runDid0142_AvailabilityDataRead_DataServices_Availability_Data_Read_Availability_Data_PRE_SAFE_haptic_warning_ReadData: start-on-event=DIA_runDid0142_AvailabilityDataRead, operation=DataServices_Availability_Data_Read_Availability_Data_PRE_SAFE_haptic_warning.ReadData
        OIT_DIA_runDid0241_PRE_SAFE_Recorder_1_ConditionCheckRead_DataServices_PRE_SAFE_Recorder_1_read_Read_CombinedDataElement30DE2423: start-on-event=DIA_runDid0241_PRE_SAFE_Recorder_1_ConditionCheckRead, operation=DataServices_PRE_SAFE_Recorder_1_read_Read_CombinedDataElement.ConditionCheckRead
        OIT_DIA_runDid0241_PRE_SAFE_Recorder_1_ReadData_DataServices_PRE_SAFE_Recorder_1_read_Read_CombinedDataElement_ReadData: start-on-event=DIA_runDid0241_PRE_SAFE_Recorder_1_ReadData, operation=DataServices_PRE_SAFE_Recorder_1_read_Read_CombinedDataElement.ReadData
        OIT_DIA_runDid0241_PRE_SAFE_Recorder_1_ReadDataLength_DataServices_PRE_SAFE_Recorder_1_read_Read_CombinedDataElement_Rea975458D6: start-on-event=DIA_runDid0241_PRE_SAFE_Recorder_1_ReadDataLength, operation=DataServices_PRE_SAFE_Recorder_1_read_Read_CombinedDataElement.ReadDataLength
        OIT_DIA_runDid0241_PRE_SAFE_Recorder_1_WriteData_DataServices_PRE_SAFE_Recorder_1_read_Read_CombinedDataElement_WriteData: start-on-event=DIA_runDid0241_PRE_SAFE_Recorder_1_WriteData, operation=DataServices_PRE_SAFE_Recorder_1_read_Read_CombinedDataElement.WriteData
        OIT_DIA_runDid0242_PRE_SAFE_Recorder_2_ConditionCheckRead_DataServices_PRE_SAFE_Recorder_2_read_Read_CombinedDataElement0331EA24: start-on-event=DIA_runDid0242_PRE_SAFE_Recorder_2_ConditionCheckRead, operation=DataServices_PRE_SAFE_Recorder_2_read_Read_CombinedDataElement.ConditionCheckRead
        OIT_DIA_runDid0242_PRE_SAFE_Recorder_2_ReadData_DataServices_PRE_SAFE_Recorder_2_read_Read_CombinedDataElement_ReadData: start-on-event=DIA_runDid0242_PRE_SAFE_Recorder_2_ReadData, operation=DataServices_PRE_SAFE_Recorder_2_read_Read_CombinedDataElement.ReadData
        OIT_DIA_runDid0242_PRE_SAFE_Recorder_2_ReadDataLength_DataServices_PRE_SAFE_Recorder_2_read_Read_CombinedDataElement_Rea394922B5: start-on-event=DIA_runDid0242_PRE_SAFE_Recorder_2_ReadDataLength, operation=DataServices_PRE_SAFE_Recorder_2_read_Read_CombinedDataElement.ReadDataLength
        OIT_DIA_runDid0242_PRE_SAFE_Recorder_2_WriteData_DataServices_PRE_SAFE_Recorder_2_read_Read_CombinedDataElement_WriteData: start-on-event=DIA_runDid0242_PRE_SAFE_Recorder_2_WriteData, operation=DataServices_PRE_SAFE_Recorder_2_read_Read_CombinedDataElement.WriteData
        OIT_DIA_runDid0200_CAN_input_Read_Neues_Bitfeld_1_ReadData_DataServices_CAN_input_Read_Neues_Bitfeld_1_ReadData: start-on-event=DIA_runDid0200_CAN_input_Read_Neues_Bitfeld_1_ReadData, operation=DataServices_CAN_input_Read_Neues_Bitfeld_1.ReadData
        OIT_DIA_runDid0200_CAN_input_Read_Neues_Bitfeld_1_ConditionCheckRead_DataServices_CAN_input_Read_Neues_Bitfeld_1_Conditi210181F8: start-on-event=DIA_runDid0200_CAN_input_Read_Neues_Bitfeld_1_ConditionCheckRead, operation=DataServices_CAN_input_Read_Neues_Bitfeld_1.ConditionCheckRead
        OIT_Runnable_DataServices_CAN_input_Read_Neues_Bitfeld_2_ConditionCheckRead: start-on-event=DIA_runDid0200_CAN_input_Read_Neues_Bitfeld_2_ConditionCheckRead, operation=DataServices_CAN_input_Read_Neues_Bitfeld_2.ConditionCheckRead
        OIT_Runnable_DataServices_CAN_input_Read_Neues_Bitfeld_2_ReadData: start-on-event=DIA_runDid0200_CAN_input_Read_Neues_Bitfeld_2_ReadData, operation=DataServices_CAN_input_Read_Neues_Bitfeld_2.ReadData
        OIT_DIA_runDid0200_CAN_input_Read_Neues_Bitfeld_{3..6}_ReadData_DataServices_CAN_input_Read_Neues_Bitfeld_{3..6}_ReadData: start-on-event=DIA_runDid0200_CAN_input_Read_Neues_Bitfeld_{3..6}_ReadData, operation=DataServices_CAN_input_Read_Neues_Bitfeld_{3..6}.ReadData
        OIT_DIA_runDid0200_CAN_input_Read_Battery_ReadData_DataServices_CAN_input_Read_Supply_battery_voltage_ReadData: start-on-event=DIA_runDid0200_CAN_input_Read_Supply_battery_voltage_ReadData, operation=DataServices_CAN_input_Read_Supply_battery_voltage.ReadData
        OIT_DIA_runDid0200_CAN_input_Read_Neues_Bitfeld_3_ConditionCheckRead_DataServices_CAN_input_Read_Neues_Bitfeld_3_ConditiE7305E88: start-on-event=DIA_runDid0200_CAN_input_Read_Neues_Bitfeld_3_ConditionCheckRead, operation=DataServices_CAN_input_Read_Neues_Bitfeld_3.ConditionCheckRead
        OIT_DIA_runDid0200_CAN_input_Read_Neues_Bitfeld_4_ConditionCheckRead_DataServices_CAN_input_Read_Neues_Bitfeld_4_Conditi150BD6E1: start-on-event=DIA_runDid0200_CAN_input_Read_Neues_Bitfeld_4_ConditionCheckRead, operation=DataServices_CAN_input_Read_Neues_Bitfeld_4.ConditionCheckRead
        OIT_DIA_runDid0200_CAN_input_Read_Neues_Bitfeld_5_ConditionCheckRead_DataServices_CAN_input_Read_Neues_Bitfeld_5_Conditi76133959: start-on-event=DIA_runDid0200_CAN_input_Read_Neues_Bitfeld_5_ConditionCheckRead, operation=DataServices_CAN_input_Read_Neues_Bitfeld_5.ConditionCheckRead
        OIT_DIA_runDid0200_CAN_input_Read_Neues_Bitfeld_6_ConditionCheckRead_DataServices_CAN_input_Read_Neues_Bitfeld_6_ConditiD33A0991: start-on-event=DIA_runDid0200_CAN_input_Read_Neues_Bitfeld_6_ConditionCheckRead, operation=DataServices_CAN_input_Read_Neues_Bitfeld_6.ConditionCheckRead
        OIT_DIA_runDid0200_CAN_input_Read_Supply_battery_voltage_ConditionCheckRead_DataServices_CAN_input_Read_Supply_battery_v0AC68809: start-on-event=DIA_runDid0200_CAN_input_Read_Supply_battery_voltage_ConditionCheckRead, operation=DataServices_CAN_input_Read_Supply_battery_voltage.ConditionCheckRead
        OIT_DIA_runDid0200_CAN_input_Read_RBTMFL_Sp_Lvl_Rq_ST3_ConditionCheckRead_DataServices_CAN_input_Read_Neues_Bitfeld_7_Co79465C0A: start-on-event=DIA_runDid0200_CAN_input_Read_Neues_Bitfeld_7_ConditionCheckRead, operation=DataServices_CAN_input_Read_Neues_Bitfeld_7.ConditionCheckRead
        OIT_DIA_runDid0200_CAN_input_Read_RBTMFL_Sp_Lvl_Rq_ST3_ReadData_DataServices_CAN_input_Read_Neues_Bitfeld_7_ReadData: start-on-event=DIA_runDid0200_CAN_input_Read_Neues_Bitfeld_7_ReadData, operation=DataServices_CAN_input_Read_Neues_Bitfeld_7.ReadData
        OIT_DIA_runDid0200_CAN_input_Read_Neues_Bitfeld_8_ConditionCheckRead_DataServices_CAN_input_Read_Neues_Bitfeld_8_ConditiEC3C1F02: start-on-event=DIA_runDid0200_CAN_input_Read_Neues_Bitfeld_8_ConditionCheckRead, operation=DataServices_CAN_input_Read_Neues_Bitfeld_8.ConditionCheckRead
        OIT_DIA_runDid0200_CAN_input_Read_Neues_Bitfeld_8_ReadData_DataServices_CAN_input_Read_Neues_Bitfeld_8_ReadData: start-on-event=DIA_runDid0200_CAN_input_Read_Neues_Bitfeld_8_ReadData, operation=DataServices_CAN_input_Read_Neues_Bitfeld_8.ReadData
        OIT_DIA_runDidFD01_SWVersionConditionCheckRead_DataServices_SW_Version_Read_SW_Version_ConditionCheckRead: start-on-event=DIA_runDidFD01_SWVersionConditionCheckRead, operation=DataServices_SW_Version_Read_SW_Version.ConditionCheckRead
        OIT_DIA_runDidFD01_SWVersionRead_DataServices_SW_Version_Read_SW_Version_ReadData: start-on-event=DIA_runDidFD01_SWVersionRead, operation=DataServices_SW_Version_Read_SW_Version.ReadData
        OIT_DIA_runDid00140_Obsolescence_Data_BSR_Current_Value_Read_DataServices_Obsolescence_Data_Read_Obsolescence_Data_BSR_C00C8DC55: start-on-event=DIA_runDid00140_Obsolescence_Data_BSR_Current_Value_Read, operation=DataServices_Obsolescence_Data_Read_Obsolescence_Data_BSR_Current_Value.ReadData
        OIT_DIA_runDid00140_Obsolescence_Data_BSR_Threshold_Yellow_To_Red_Read_DataServices_Obsolescence_Data_Read_Obsolescence_6D22202C: start-on-event=DIA_runDid00140_Obsolescence_Data_BSR_Threshold_Yellow_To_Red_Read, operation=DataServices_Obsolescence_Data_Read_Obsolescence_Data_BSR_Threshold_Yellow_to_Red.ReadData
        OIT_DIA_runDid00140_Obsolescence_Data_BSR_Threshold_Green_To_Yellow_Read_DataServices_Obsolescence_Data_Read_ObsolescencA56AC932: start-on-event=DIA_runDid00140_Obsolescence_Data_BSR_Threshold_Green_To_Yellow_Read, operation=DataServices_Obsolescence_Data_Read_Obsolescence_Data_BSR_Threshold_Green_to_Yellow.ReadData
        OIT_DIA_runDid00140_Obsolescence_Data_PRE_CRASH_Current_Value_Read_DataServices_Obsolescence_Data_Read_Obsolescence_DataBF6DB0D6: start-on-event=DIA_runDid00140_Obsolescence_Data_PRE_CRASH_Current_Value_Read, operation=DataServices_Obsolescence_Data_Read_Obsolescence_Data_PRE_CRASH_Current_Value.ReadData
        OIT_DIA_runDid00140_Obsolescence_Data_PRE_CRASH_Treshold_Green_To_Yellow_Read_DataServices_Obsolescence_Data_Read_Obsole9C7AA126: start-on-event=DIA_runDid00140_Obsolescence_Data_PRE_CRASH_Treshold_Green_To_Yellow_Read, operation=DataServices_Obsolescence_Data_Read_Obsolescence_Data_PRE_CRASH_Threshold_Green_to_Yellow.ReadData
        OIT_DIA_runDid00140_Obsolescence_Data_PRE_CRASH_Treshold_Yellow_To_Red_Read_DataServices_Obsolescence_Data_Read_Obsolesc72B05381: start-on-event=DIA_runDid00140_Obsolescence_Data_PRE_CRASH_Treshold_Yellow_To_Red_Read, operation=DataServices_Obsolescence_Data_Read_Obsolescence_Data_PRE_CRASH_Threshold_Yellow_to_Red.ReadData
        OIT_DIA_runDid00140_Obsolescence_Data_Haptic_Warning_Current_Value_Read_DataServices_Obsolescence_Data_Read_Obsolescence37C353F5: start-on-event=DIA_runDid00140_Obsolescence_Data_Haptic_Warning_Current_Value_Read, operation=DataServices_Obsolescence_Data_Read_Obsolescence_Data_haptic_Warning_Current_Value.ReadData
        OIT_DIA_runDid00140_Obsolescence_Data_Haptic_Warning_Treshold_Green_To_Yellow_Read_DataServices_Obsolescence_Data_Read_OF89B0F7F: start-on-event=DIA_runDid00140_Obsolescence_Data_Haptic_Warning_Treshold_Green_To_Yellow_Read, operation=DataServices_Obsolescence_Data_Read_Obsolescence_Data_haptic_Warning_Threshold_Green_to_Yellow.ReadData
        OIT_DIA_runDid00140_Obsolescence_Data_Haptic_Warning_Treshold_Yellow_To_Red_Read_DataServices_Obsolescence_Data_Read_ObsB08F30C9: start-on-event=DIA_runDid00140_Obsolescence_Data_Haptic_Warning_Treshold_Yellow_To_Red_Read, operation=DataServices_Obsolescence_Data_Read_Obsolescence_Data_haptic_Warning_Threshold_Yellow_to_Red.ReadData
        OIT_DIA_runDid00140_Obsolescence_Data_PRE_SAFE_Lvl_4_5_Current_Value_Read_DataServices_Obsolescence_Data_Read_Obsolescen76F4F360: start-on-event=DIA_runDid00140_Obsolescence_Data_PRE_SAFE_Lvl_4_5_Current_Value_Read, operation=DataServices_Obsolescence_Data_Read_Obsolescence_Data_PRE_SAFE_Lvl_4_5_Current_Value.ReadData
        OIT_DIA_runDid00140_Obsolescence_Data_PRE_SAFE_Lvl_4_5_Treshold_Green_To_Yellow_Read_DataServices_Obsolescence_Data_ReadDB6D37E8: start-on-event=DIA_runDid00140_Obsolescence_Data_PRE_SAFE_Lvl_4_5_Treshold_Green_To_Yellow_Read, operation=DataServices_Obsolescence_Data_Read_Obsolescence_Data_PRE_SAFE_Lvl_4_5_Threshold_Green_to_Yellow.ReadData
        OIT_DIA_runDid00140_Obsolescence_Data_PRE_SAFE_Lvl_4_5_Treshold_Yellow_To_Red_Read_DataServices_Obsolescence_Data_Read_O3F29F47F: start-on-event=DIA_runDid00140_Obsolescence_Data_PRE_SAFE_Lvl_4_5_Treshold_Yellow_To_Red_Read, operation=DataServices_Obsolescence_Data_Read_Obsolescence_Data_PRE_SAFE_Lvl_4_5_Threshold_Yellow_to_Red.ReadData
        OIT_DIA_runDid00140_Obsolescence_Data_BSR_Current_Value_ConditionCheckRead_DataServices_Obsolescence_Data_Read_ObsolesceF0EA211A: start-on-event=DIA_runDid00140_Obsolescence_Data_BSR_Current_Value_ConditionCheckRead, operation=DataServices_Obsolescence_Data_Read_Obsolescence_Data_BSR_Current_Value.ConditionCheckRead
        OIT_DIA_runDid00140_Obsolescence_Data_BSR_Threshold_Green_To_Yellow_ConditionCheckRead_DataServices_Obsolescence_Data_Re8DD31C25: start-on-event=DIA_runDid00140_Obsolescence_Data_BSR_Threshold_Green_To_Yellow_ConditionCheckRead, operation=DataServices_Obsolescence_Data_Read_Obsolescence_Data_BSR_Threshold_Green_to_Yellow.ConditionCheckRead
        OIT_DIA_runDid00140_Obsolescence_Data_BSR_Threshold_Yellow_To_Red_ConditionCheckRead_DataServices_Obsolescence_Data_ReadB97F8E9C: start-on-event=DIA_runDid00140_Obsolescence_Data_BSR_Threshold_Yellow_To_Red_ConditionCheckRead, operation=DataServices_Obsolescence_Data_Read_Obsolescence_Data_BSR_Threshold_Yellow_to_Red.ConditionCheckRead
        OIT_DIA_runDid00140_Obsolescence_Data_Haptic_Warning_Current_Value_ConditionCheckRead_DataServices_Obsolescence_Data_Rea496E48FF: start-on-event=DIA_runDid00140_Obsolescence_Data_Haptic_Warning_Current_Value_ConditionCheckRead, operation=DataServices_Obsolescence_Data_Read_Obsolescence_Data_haptic_Warning_Current_Value.ConditionCheckRead
        OIT_DIA_runDid00140_Obsolescence_Data_Haptic_Warning_Treshold_Green_To_Yellow_ConditionCheckRead_DataServices_Obsolescen2061D55D: start-on-event=DIA_runDid00140_Obsolescence_Data_Haptic_Warning_Treshold_Green_To_Yellow_ConditionCheckRead, operation=DataServices_Obsolescence_Data_Read_Obsolescence_Data_haptic_Warning_Threshold_Green_to_Yellow.ConditionCheckRead
        OIT_DIA_runDid00140_Obsolescence_Data_Haptic_Warning_Treshold_Yellow_To_Red_ConditionCheckRead_DataServices_Obsolescence54E382D2: start-on-event=DIA_runDid00140_Obsolescence_Data_Haptic_Warning_Treshold_Yellow_To_Red_ConditionCheckRead, operation=DataServices_Obsolescence_Data_Read_Obsolescence_Data_haptic_Warning_Threshold_Yellow_to_Red.ConditionCheckRead
        OIT_DIA_runDid00140_Obsolescence_Data_PRE_CRASH_Current_Value_ConditionCheckRead_DataServices_Obsolescence_Data_Read_ObsF68D17D1: start-on-event=DIA_runDid00140_Obsolescence_Data_PRE_CRASH_Current_Value_ConditionCheckRead, operation=DataServices_Obsolescence_Data_Read_Obsolescence_Data_PRE_CRASH_Current_Value.ConditionCheckRead
        OIT_DIA_runDid00140_Obsolescence_Data_PRE_CRASH_Treshold_Green_To_Yellow_ConditionCheckRead_DataServices_Obsolescence_DaE6504463: start-on-event=DIA_runDid00140_Obsolescence_Data_PRE_CRASH_Treshold_Green_To_Yellow_ConditionCheckRead, operation=DataServices_Obsolescence_Data_Read_Obsolescence_Data_PRE_CRASH_Threshold_Green_to_Yellow.ConditionCheckRead
        OIT_DIA_runDid00140_Obsolescence_Data_PRE_CRASH_Treshold_Yellow_To_Red_ConditionCheckRead_DataServices_Obsolescence_Data869517E0: start-on-event=DIA_runDid00140_Obsolescence_Data_PRE_CRASH_Treshold_Yellow_To_Red_ConditionCheckRead, operation=DataServices_Obsolescence_Data_Read_Obsolescence_Data_PRE_CRASH_Threshold_Yellow_to_Red.ConditionCheckRead
        OIT_DIA_runDid00140_Obsolescence_Data_PRE_SAFE_Lvl_4_5_Current_Value_ConditionCheckRead_DataServices_Obsolescence_Data_RB36EA052: start-on-event=DIA_runDid00140_Obsolescence_Data_PRE_SAFE_Lvl_4_5_Current_Value_ConditionCheckRead, operation=DataServices_Obsolescence_Data_Read_Obsolescence_Data_PRE_SAFE_Lvl_4_5_Current_Value.ConditionCheckRead
        OIT_DIA_runDid00140_Obsolescence_Data_PRE_SAFE_Lvl_4_5_Treshold_Green_To_Yellow_ConditionCheckRead_DataServices_ObsolescB26C12C7: start-on-event=DIA_runDid00140_Obsolescence_Data_PRE_SAFE_Lvl_4_5_Treshold_Green_To_Yellow_ConditionCheckRead, operation=DataServices_Obsolescence_Data_Read_Obsolescence_Data_PRE_SAFE_Lvl_4_5_Threshold_Green_to_Yellow.ConditionCheckRead
        OIT_DIA_runDid00140_Obsolescence_Data_PRE_SAFE_Lvl_4_5_Treshold_Yellow_To_Red_ConditionCheckRead_DataServices_Obsolescen1BCCC731: start-on-event=DIA_runDid00140_Obsolescence_Data_PRE_SAFE_Lvl_4_5_Treshold_Yellow_To_Red_ConditionCheckRead, operation=DataServices_Obsolescence_Data_Read_Obsolescence_Data_PRE_SAFE_Lvl_4_5_Threshold_Yellow_to_Red.ConditionCheckRead
        OIT_DIA_runDidFD50_Hardware_Version_Information_Write_HW_patch_level_DataServices_Hardware_Version_Information_Write_HW_F4FA82A4: start-on-event=DIA_runDidFD50_Hardware_Version_Information_Write_HW_patch_level, operation=DataServices_Hardware_Version_Information_Write_HW_patch_level.WriteData
        OIT_DIA_runDidFD50_Hardware_Version_Information_Write_HW_week_DataServices_Hardware_Version_Information_Write_HW_week_WriteData: start-on-event=DIA_runDidFD50_Hardware_Version_Information_Write_HW_week, operation=DataServices_Hardware_Version_Information_Write_HW_week.WriteData
        OIT_DIA_runDidFD50_Hardware_Version_Information_Write_HW_year_DataServices_Hardware_Version_Information_Write_HW_year_WriteData: start-on-event=DIA_runDidFD50_Hardware_Version_Information_Write_HW_year, operation=DataServices_Hardware_Version_Information_Write_HW_year.WriteData
        OIT_DIA_runDid0210_CAN_output_Read_CANoutput1_ConditionCheckRead_DataServices_CAN_output_Read_CANoutput1_ConditionCheckRead: start-on-event=DIA_runDid0210_CAN_output_Read_CANoutput1_ConditionCheckRead, operation=DataServices_CAN_output_Read_CANoutput1.ConditionCheckRead
        OIT_DIA_runDid0210_CAN_output_Read_CANoutput1_ReadData_DataServices_CAN_output_Read_CANoutput1_ReadData: start-on-event=DIA_runDid0210_CAN_output_Read_CANoutput1_ReadData, operation=DataServices_CAN_output_Read_CANoutput1.ReadData
        OIT_DIA_runDid0210_CAN_output_Read_PS_Curve_XX_Stat_ST3_ConditionCheckRead_DataServices_CAN_output_Read_PS_Curve_XX_Stat55857E0A: start-on-event=DIA_runDid0210_CAN_output_Read_PS_Curve_XX_Stat_ST3_ConditionCheckRead, operation=DataServices_CAN_output_Read_PS_Curve_XX_Stat_ST3.ConditionCheckRead
        OIT_DIA_runDid0210_CAN_output_Read_PS_Curve_XX_Stat_ST3_ReadData_DataServices_CAN_output_Read_PS_Curve_XX_Stat_ST3_ReadData: start-on-event=DIA_runDid0210_CAN_output_Read_PS_Curve_XX_Stat_ST3_ReadData, operation=DataServices_CAN_output_Read_PS_Curve_XX_Stat_ST3.ReadData
        OIT_DIA_runDid0210_CAN_output_Read_RBTMxx_Actv_Lvl_ST35_ConditionCheckRead_DataServices_CAN_output_Read_RBTMxx_Actv_Lvl_FFE6C013: start-on-event=DIA_runDid0210_CAN_output_Read_RBTMxx_Actv_Lvl_ST35_ConditionCheckRead, operation=DataServices_CAN_output_Read_RBTMxx_Actv_Lvl_ST35.ConditionCheckRead
        OIT_DIA_runDid0210_CAN_output_Read_RBTMxx_Actv_Lvl_ST35_ReadData_DataServices_CAN_output_Read_RBTMxx_Actv_Lvl_ST35_ReadData: start-on-event=DIA_runDid0210_CAN_output_Read_RBTMxx_Actv_Lvl_ST35_ReadData, operation=DataServices_CAN_output_Read_RBTMxx_Actv_Lvl_ST35.ReadData
        OIT_DIA_runDid0210_CAN_output_Read_RBTMxx_SP_ActvClient_ST35_ConditionCheckRead_DataServices_CAN_output_Read_RBTMxx_SP_AFD796A39: start-on-event=DIA_runDid0210_CAN_output_Read_RBTMxx_SP_ActvClient_ST35_ConditionCheckRead, operation=DataServices_CAN_output_Read_RBTMxx_SP_ActvClient_ST35.ConditionCheckRead
        OIT_DIA_runDid0210_CAN_output_Read_RBTMxx_SP_ActvClient_ST35_ReadData_DataServices_CAN_output_Read_RBTMxx_SP_ActvClient_6A2522B8: start-on-event=DIA_runDid0210_CAN_output_Read_RBTMxx_SP_ActvClient_ST35_ReadData, operation=DataServices_CAN_output_Read_RBTMxx_SP_ActvClient_ST35.ReadData
        OIT_DIA_runDid0210_CAN_output_Read_RBTMxx_SP_FctPrecond_Stat_ST35_ConditionCheckRead_DataServices_CAN_output_Read_RBTMxx2F0312EA: start-on-event=DIA_runDid0210_CAN_output_Read_RBTMxx_SP_FctPrecond_Stat_ST35_ConditionCheckRead, operation=DataServices_CAN_output_Read_RBTMxx_SP_FctPrecond_Stat_ST35.ConditionCheckRead
        OIT_DIA_runDid0210_CAN_output_Read_RBTMxx_SP_FctPrecond_Stat_ST35_ReadData_DataServices_CAN_output_Read_RBTMxx_SP_FctPre43D57E5D: start-on-event=DIA_runDid0210_CAN_output_Read_RBTMxx_SP_FctPrecond_Stat_ST35_ReadData, operation=DataServices_CAN_output_Read_RBTMxx_SP_FctPrecond_Stat_ST35.ReadData
        OIT_DIA_runDid0220_HW_input_Read_Voltage_KL30t_ConditionCheckRead_DataServices_HW_input_Read_Voltage_KL30t_ConditionCheckRead: start-on-event=DIA_runDid0220_HW_input_Read_Voltage_KL30t_ConditionCheckRead, operation=DataServices_HW_input_Read_Voltage_KL30t.ConditionCheckRead
        OIT_DIA_runDid0220_HW_input_Read_Voltage_KL30t_ReadData_DataServices_HW_input_Read_Voltage_KL30t_ReadData: start-on-event=DIA_runDid0220_HW_input_Read_Voltage_KL30t_ReadData, operation=DataServices_HW_input_Read_Voltage_KL30t.ReadData
        OIT_DIA_runDid0220_HW_input_Read_Voltage_Motor_ConditionCheckRead_DataServices_HW_input_Read_Voltage_Motor_ConditionCheckRead: start-on-event=DIA_runDid0220_HW_input_Read_Voltage_Motor_ConditionCheckRead, operation=DataServices_HW_input_Read_Voltage_Motor.ConditionCheckRead
        OIT_DIA_runDid0220_HW_input_Read_Voltage_Motor_ReadData_DataServices_HW_input_Read_Voltage_Motor_ReadData: start-on-event=DIA_runDid0220_HW_input_Read_Voltage_Motor_ReadData, operation=DataServices_HW_input_Read_Voltage_Motor.ReadData
        OIT_DIA_runDid0240_Internal_ECU_information_Read_ECU_Temperature_ConditionCheckRead_DataServices_Internal_ECU_informatio7856E4D2: start-on-event=DIA_runDid0240_Internal_ECU_information_Read_ECU_Temperature_ConditionCheckRead, operation=DataServices_Internal_ECU_information_Read_ECU_Temperature.ConditionCheckRead
        OIT_DIA_runDid0240_Internal_ECU_information_Read_ECU_Temperature_ReadData_DataServices_Internal_ECU_information_Read_ECU027DCDDD: start-on-event=DIA_runDid0240_Internal_ECU_information_Read_ECU_Temperature_ReadData, operation=DataServices_Internal_ECU_information_Read_ECU_Temperature.ReadData
        OIT_DIA_runDid0240_Internal_ECU_information_Read_MOTOR_Current_ConditionCheckRead_DataServices_Internal_ECU_information_97CD9CA8: start-on-event=DIA_runDid0240_Internal_ECU_information_Read_MOTOR_Current_ConditionCheckRead, operation=DataServices_Internal_ECU_information_Read_MOTOR_Current.ConditionCheckRead
        OIT_DIA_runDid0240_Internal_ECU_information_Read_MOTOR_Current_ReadData_DataServices_Internal_ECU_information_Read_MOTORAFD19C80: start-on-event=DIA_runDid0240_Internal_ECU_information_Read_MOTOR_Current_ReadData, operation=DataServices_Internal_ECU_information_Read_MOTOR_Current.ReadData
        OIT_DIA_runDid0240_Internal_ECU_information_Read_Autosar_System_State_EcuM_State_ReadData_DataServices_Internal_ECU_info526A40CE: start-on-event=DIA_runDid0240_Internal_ECU_information_Read_Autosar_System_State_EcuM_State_ReadData, operation=DataServices_Internal_ECU_information_Read_Autosar_System_State_EcuM_State.ReadData
        OIT_DIA_runDid0240_Internal_ECU_information_Read_Autosar_System_State_EcuM_State_ConditionCheckRead_DataServices_InternaECAAFFC8: start-on-event=DIA_runDid0240_Internal_ECU_information_Read_Autosar_System_State_EcuM_State_ConditionCheckRead, operation=DataServices_Internal_ECU_information_Read_Autosar_System_State_EcuM_State.ConditionCheckRead
        OIT_DIA_runDidFD03_ECUTraceablityNumberConditionCheckRead_DataServices_ECU_serial_number_Read_ECU_traceability_number_CoFBDAAA93: start-on-event=DIA_runDidFD03_ECUTraceabilityNumberConditionCheckRead, operation=DataServices_ECU_serial_number_Read_ECU_traceability_number.ConditionCheckRead
        OIT_DIA_runDidFD03_ECUTraceablityNumberRead_DataServices_ECU_serial_number_Read_ECU_traceability_number_ReadData: start-on-event=DIA_runDidFD03_ECUTraceabilityNumberRead, operation=DataServices_ECU_serial_number_Read_ECU_traceability_number.ReadData
        OIT_DIA_runDidFD03_ECUTraceablityNumberWrite_DataServices_ECU_serial_number_Read_ECU_traceability_number_WriteData: start-on-event=DIA_runDidFD03_ECUTraceabilityNumberWrite, operation=DataServices_ECU_serial_number_Read_ECU_traceability_number.WriteData
        OIT_DIA_runDidFD03_PCBAProgrammedPartNumberConditionCheckRead_DataServices_ECU_serial_number_Read_PCBA_Programmed_Part_nB85DF4E7: start-on-event=DIA_runDidFD03_PCBAProgrammedPartNumberConditionCheckRead, operation=DataServices_ECU_serial_number_Read_PCBA_Programmed_Part_number.ConditionCheckRead
        OIT_DIA_runDidFD03_PCBAProgrammedPartNumberWrite_DataServices_ECU_serial_number_Read_PCBA_Programmed_Part_number_WriteData: start-on-event=DIA_runDidFD03_PCBAProgrammedPartNumberWrite, operation=DataServices_ECU_serial_number_Read_PCBA_Programmed_Part_number.WriteData
        OIT_DIA_runDidFD03_PCBAProgrammedPartNumberRead_DataServices_ECU_serial_number_Read_PCBA_Programmed_Part_number_ReadData: start-on-event=DIA_runDidFD03_PCBAProgrammedPartNumberRead, operation=DataServices_ECU_serial_number_Read_PCBA_Programmed_Part_number.ReadData
        OIT_DIA_runRid0203_CheckProgrammingPreconditions_RoutineServices_Routine_Check_Reprogramming_Preconditions_Start_Start: start-on-event=DIA_runRid0203_CheckProgrammingPreconditionsStart, operation=RoutineServices_Routine_Check_Reprogramming_Preconditions_Start.Start
        OIT_DIA_runDidFD30_Temperature_Sensor_Calibration_Point_Read_Offset_Point_ReadData_DataServices_Temperature_Sensor_CalibCBC92B71: start-on-event=DIA_runDidFD30_Temperature_Sensor_Calibration_Point_Read_Offset_Point_ReadData, operation=DataServices_Temperature_Sensor_Calibration_Point_Read_Offset_Point.ReadData
        OIT_DIA_runDidFD30_Temperature_Sensor_Calibration_Point_Read_Offset_Point_ConditionCheckRead_DataServices_Temperature_SeA5A6BE9A: start-on-event=DIA_runDidFD30_Temperature_Sensor_Calibration_Point_Read_Offset_Point_ConditionCheckRead, operation=DataServices_Temperature_Sensor_Calibration_Point_Read_Offset_Point.ConditionCheckRead
        OIT_DIA_runDidFD30_Temperature_Sensor_Calibration_Point_Read_Offset_Point_WriteData_DataServices_Temperature_Sensor_CaliF12AE0B2: start-on-event=DIA_runDidFD30_Temperature_Sensor_Calibration_Point_Read_Offset_Point_WriteData, operation=DataServices_Temperature_Sensor_Calibration_Point_Read_Offset_Point.WriteData
        OIT_DIA_runDidFDDF_Velocity_PI_Regulation_Coefficient_Read_Input_Velocity_Coefficient_ConditionCheckRead_DataServices_Ve12E43360: start-on-event=DIA_runDidFDDF_Velocity_PI_Regulation_Coefficient_Read_Input_Velocity_Coefficient_ConditionCheckRead, operation=DataServices_Velocity_PI_Regulation_Coefficient_Read_Input_Velocity_Coefficient.ConditionCheckRead
        OIT_DIA_runDidFDDF_Velocity_PI_Regulation_Coefficient_Read_Input_Velocity_Coefficient_ReadData_DataServices_Velocity_PI_ACB017A1: start-on-event=DIA_runDidFDDF_Velocity_PI_Regulation_Coefficient_Read_Input_Velocity_Coefficient_ReadData, operation=DataServices_Velocity_PI_Regulation_Coefficient_Read_Input_Velocity_Coefficient.ReadData
        OIT_DIA_runDidFDDF_Velocity_PI_Regulation_Coefficient_Read_Input_Velocity_Coefficient_WriteData_DataServices_Velocity_PI894AEF74: start-on-event=DIA_runDidFDDF_Velocity_PI_Regulation_Coefficient_Read_Input_Velocity_Coefficient_WriteData, operation=DataServices_Velocity_PI_Regulation_Coefficient_Read_Input_Velocity_Coefficient.WriteData
      explicit-inter-runnable-variables:
        data u8DiagRequestedCycle: sw-calibration-access=READ-ONLY, type=u8CycleNumberType_Appl, init-value=constant-reference=APPLINIT_KU8_CYCLE_NUMBER_NONE  # Cycle identifier requested by Start routine
      136 x runnable:
        DIA_runDidF18C_EcuSerialNumberRead
        DIA_runDidF18C_EcuSerialNumberWrite
        DIA_runDidFD2F_EcuLocationRead: can-be-invoked-concurrently=true
        DIA_runDidFD2F_EcuLocationWrite: can-be-invoked-concurrently=true
          sync call SC_NvMService_NVP_BLOCK_ID_ECU_LOCATION_WriteBlock: operation=NvMService_NVP_BLOCK_ID_ECU_LOCATION.WriteBlock
          sync call SC_NvMService_NVP_BLOCK_ID_ECU_LOCATION_GetErrorStatus: operation=NvMService_NVP_BLOCK_ID_ECU_LOCATION.GetErrorStatus
        DIA_runDidFD2A_StepsLibraryRead
        DIA_runDidFD2A_StepsLibraryWrite
          sync call SC_NvMService_NVP_BLOCK_ID_STEP_WriteBlock: operation=NvMService_NVP_BLOCK_ID_STEP.WriteBlock
          sync call SC_NvMService_NVP_BLOCK_ID_STEP_GetErrorStatus: operation=NvMService_NVP_BLOCK_ID_STEP.GetErrorStatus
        DIA_runDidFD10_CycleConfigurationWrite
          sync call SC_NvMService_NVP_BLOCK_ID_CYCLE_WriteBlock: operation=NvMService_NVP_BLOCK_ID_CYCLE.WriteBlock
          sync call SC_NvMService_NVP_BLOCK_ID_CYCLE_GetErrorStatus: operation=NvMService_NVP_BLOCK_ID_CYCLE.GetErrorStatus
        DIA_runDidFD10_CycleConfigurationRead
        DIA_runDid0340_UniqueSeatbeltSerialNumberRead
        DIA_runDid0340_UniqueSeatbeltSerialNumberWrite
          sync call SC_NvMService_NVP_BLOCK_ID_BELT_ASSEMBLY_MANUF_DATE_AND_SN_WriteBlock: operation=NvMService_NVP_BLOCK_ID_BELT_ASSEMBLY_MANUF_DATE_AND_SN.WriteBlock
        DIA_runDid0340_UniqueSeatbeltSerialNumberConditionCheckRead
        DIA_runDidF18C_EcuSerialNumberReadDataLength
        DIA_runDidF18C_EcuSerialNumberConditionCheckRead
        DIA_runDidFEFF_MeasuruementFrameConfigurationRead
          sync call SC_NvMService_NVP_BLOCK_ID_MEASUREMENT_FRAME_CONFIG_GetErrorStatus: operation=NvMService_NVP_BLOCK_ID_MEASUREMENT_FRAME_CONFIG.GetErrorStatus
          sync call SC_NvMService_NVP_BLOCK_ID_MEASUREMENT_FRAME_CONFIG_ReadBlock: operation=NvMService_NVP_BLOCK_ID_MEASUREMENT_FRAME_CONFIG.ReadBlock
        DIA_runDidFD09_LastWarmResetRead_LastDetectedWarmResetCause
        DIA_runDidFD09_LastWarmResetRead_ResetCauseCounter
        DIA_runDidFEFF_MeasuruementFrameConfigurationWrite
          sync call SC_NvMService_NVP_BLOCK_ID_MEASUREMENT_FRAME_12_CONFIG_WriteBlock: operation=NvMService_NVP_BLOCK_ID_MEASUREMENT_FRAME_12_CONFIG.WriteBlock
          sync call SC_NvMService_NVP_BLOCK_ID_MEASUREMENT_FRAME_CONFIG_WriteBlock: operation=NvMService_NVP_BLOCK_ID_MEASUREMENT_FRAME_CONFIG.WriteBlock
          sync call SC_NvMService_NVP_BLOCK_ID_MEASUREMENT_FRAME_CONFIG_GetErrorStatus: operation=NvMService_NVP_BLOCK_ID_MEASUREMENT_FRAME_CONFIG.GetErrorStatus
        DIA_runDidFEFF_MeasuruementFrameConfigurationConditionCheckRead
          sync call SC_pclAecStatus_GetAecGroupsStatus: operation=pclAecStatus.GetAecGroupsStatus
          sync call SC_pclAecStatus_GetAecStatus: operation=pclAecStatus.GetAecStatus
          sync call SC_pclAecStatus_GetNumberOfImplementedAec: operation=pclAecStatus.GetNumberOfImplementedAec
        DIA_runDidFD09_LastWarmReseConditionChecktRead_LastDetectedWarmResetCause
        DIA_runDidFD09_LastWarmResetConditionCheckRead_ResetCauseCounter
        DIA_runGetDiagRequestCycle: can-be-invoked-concurrently=true
          read-local-variables:
            access Read_u8DiagRequestedCycle: accessed-variable=u8DiagRequestedCycle
        DIA_runClearDiagRequestCycle: can-be-invoked-concurrently=true
          written-local-variables:
            access WRITE_u8DiagRequestedCycle: accessed-variable=u8DiagRequestedCycle
        DIA_runDidFD31_HBCalibrationWrite
          sync call SC_NvMService_NVP_BLOCK_ID_HB_CALIBRATION_WriteBlock: operation=NvMService_NVP_BLOCK_ID_HB_CALIBRATION.WriteBlock
          sync call SC_NvMService_NVP_BLOCK_ID_HB_CALIBRATION_GetErrorStatus: operation=NvMService_NVP_BLOCK_ID_HB_CALIBRATION.GetErrorStatus
        DIA_runDidFD31_HBCalibrationRead
          sync call SC_NvMService_NVP_BLOCK_ID_HB_CALIBRATION_ReadBlock: operation=NvMService_NVP_BLOCK_ID_HB_CALIBRATION.ReadBlock
          sync call SC_NvMService_NVP_BLOCK_ID_HB_CALIBRATION_GetErrorStatus: operation=NvMService_NVP_BLOCK_ID_HB_CALIBRATION.GetErrorStatus
        DIA_runDidFD31_HBCalibrationWriteConditionCheckRead
        DIA_runDidFDFF_MeasurementFrameBlock12ConfigRead
          sync call SC_NvMService_NVP_BLOCK_ID_MEASUREMENT_FRAME_12_CONFIG_GetErrorStatus: operation=NvMService_NVP_BLOCK_ID_MEASUREMENT_FRAME_12_CONFIG.GetErrorStatus
          sync call SC_NvMService_NVP_BLOCK_ID_MEASUREMENT_FRAME_12_CONFIG_ReadBlock: operation=NvMService_NVP_BLOCK_ID_MEASUREMENT_FRAME_12_CONFIG.ReadBlock
        DIA_runDidFDFF_MeasurementFrameBlock12ConfigWrite
          sync call SC_NvMService_NVP_BLOCK_ID_MEASUREMENT_FRAME_12_CONFIG_WriteBlock: operation=NvMService_NVP_BLOCK_ID_MEASUREMENT_FRAME_12_CONFIG.WriteBlock
          sync call SC_NvMService_NVP_BLOCK_ID_MEASUREMENT_FRAME_12_CONFIG_GetErrorStatus: operation=NvMService_NVP_BLOCK_ID_MEASUREMENT_FRAME_12_CONFIG.GetErrorStatus
        DIA_runDidFDFF_MeasurementFrameBlock12ConfigConditionCheckRead
        DIA_runDidFE00_AECStatusRead
          sync call SC_NvMService_NVP_BLOCK_ID_AEC_STATUS_EraseBlock: operation=NvMService_NVP_BLOCK_ID_AEC_STATUS.EraseBlock
          sync call SC_NvMService_NVP_BLOCK_ID_AEC_STATUS_ReadBlock: operation=NvMService_NVP_BLOCK_ID_AEC_STATUS.ReadBlock
        DIA_runDidFE00_AECStatusReadDataLength
        DIA_runDidFE00_AECStatusConditionCheckRead
        DIA_runDidFD08_ResetCauseManagementRead
          sync call SC_icsResetCause_GetResetCause: operation=icsResetCause.GetResetCause
        DIA_runDidFD08_ResetCauseManagementConditionCheckRead
        DIA_runRidF703_CycleExecutionStart
          data-receive-point-by-arguments:
            access REC_prrExecutedCycle_u8CycleNumber: accessed-variable=prrExecutedCycle.u8CycleNumber
          read-local-variables:
            access Read_u8DiagRequestedCycle: accessed-variable=u8DiagRequestedCycle
          written-local-variables:
            access WRITE_u8DiagRequestedCycle: accessed-variable=u8DiagRequestedCycle
        DIA_runRidF703_CycleExecutionStop
          data-receive-point-by-arguments:
            access REC_prrExecutedCycle_u8CycleNumber: accessed-variable=prrExecutedCycle.u8CycleNumber
          read-local-variables:
            access Read_u8DiagRequestedCycle: accessed-variable=u8DiagRequestedCycle
          written-local-variables:
            access WRITE_u8DiagRequestedCycle: accessed-variable=u8DiagRequestedCycle
        DIA_runRidF703_CycleExecutionRequestResults
          data-receive-point-by-arguments:
            access REC_prrExecutedCycle_u8CycleNumber: accessed-variable=prrExecutedCycle.u8CycleNumber
          read-local-variables:
            access Read_u8DiagRequestedCycle: accessed-variable=u8DiagRequestedCycle
        DIA_runRid0329_TriggerBSRRequestResults
          data-receive-point-by-arguments:
            access REC_prrExecutedCycle_u8CycleNumber: accessed-variable=prrExecutedCycle.u8CycleNumber
          read-local-variables:
            access Read_u8DiagRequestedCycle: accessed-variable=u8DiagRequestedCycle
        DIA_runRid0329_TriggerBSRStart
          data-receive-point-by-arguments:
            access REC_prrExecutedCycle_u8CycleNumber: accessed-variable=prrExecutedCycle.u8CycleNumber
          written-local-variables:
            access WRITE_u8DiagRequestedCycle: accessed-variable=u8DiagRequestedCycle
        DIA_runRid0329_TriggerBSRStop
        DIA_runRid0330_TriggerTensioningCycleRequestResults
          read-local-variables:
            access Read_u8DiagRequestedCycle: accessed-variable=u8DiagRequestedCycle
        DIA_runRid0330_TriggerTensioningCycleStart
          data-receive-point-by-arguments:
            access REC_prrExecutedCycle_u8CycleNumber: accessed-variable=prrExecutedCycle.u8CycleNumber
          written-local-variables:
            access WRITE_u8DiagRequestedCycle: accessed-variable=u8DiagRequestedCycle
        DIA_runRid0330_TriggerTensioningCycleStop
        DIA_cyclicProcessingTask
          data-receive-point-by-arguments:
            access REC_IF_VehSpd_Disp_ST3_VehSpd_Disp_ST3: accessed-variable=IF_VehSpd_Disp_ST3.VehSpd_Disp_ST3
          data-send-points:
            access SEND_psePresafeDisplay_b8TriggerPreSafeRequestStatus: accessed-variable=psePresafeDisplay.b8TriggerPreSafeRequestStatus
          written-local-variables:
            access WRITE_u8DiagRequestedCycle: accessed-variable=u8DiagRequestedCycle
        DIA_runRid0302_TriggerPresafeDisplayRequestRequestResults
        DIA_runRid0302_TriggerPresafeDisplayRequestStart
        DIA_runRid0302_TriggerPresafeDisplayRequestStop
        DIA_runDid0142_AvailabilityDataRead
          data-receive-point-by-arguments:
            access REC_R_AvailabilityDataHandler_AvailabilityDataCategory: accessed-variable=R_AvailabilityDataHandler.AvailabilityDataCategory
        DIA_runDid0142_AvailabilityDataConditionsCheckRead
        DIA_runDid0241_PRE_SAFE_Recorder_1_ConditionCheckRead
          4 x sync call:
            SC_NvMService_NVP_BLOCK_ID_PRE_SAFE_RECORDER_1_EraseBlock: operation=NvMService_NVP_BLOCK_ID_PRE_SAFE_RECORDER_1.EraseBlock
            SC_NvMService_NVP_BLOCK_ID_PRE_SAFE_RECORDER_1_GetErrorStatus: operation=NvMService_NVP_BLOCK_ID_PRE_SAFE_RECORDER_1.GetErrorStatus
            SC_NvMService_NVP_BLOCK_ID_PRE_SAFE_RECORDER_1_ReadBlock: operation=NvMService_NVP_BLOCK_ID_PRE_SAFE_RECORDER_1.ReadBlock
            SC_NvMService_NVP_BLOCK_ID_PRE_SAFE_RECORDER_1_WriteBlock: operation=NvMService_NVP_BLOCK_ID_PRE_SAFE_RECORDER_1.WriteBlock
        DIA_runDid0241_PRE_SAFE_Recorder_1_ReadData
        DIA_runDid0241_PRE_SAFE_Recorder_1_ReadDataLength
        DIA_runDid0241_PRE_SAFE_Recorder_1_WriteData
          sync call SC_NvMService_NVP_BLOCK_ID_PRE_SAFE_RECORDER_1_SetRamBlockStatus: operation=NvMService_NVP_BLOCK_ID_PRE_SAFE_RECORDER_1.SetRamBlockStatus
        DIA_runDid0242_PRE_SAFE_Recorder_2_ConditionCheckRead
          4 x sync call:
            SC_NvMService_NVP_BLOCK_ID_PRE_SAFE_RECORDER_2_EraseBlock: operation=NvMService_NVP_BLOCK_ID_PRE_SAFE_RECORDER_2.EraseBlock
            SC_NvMService_NVP_BLOCK_ID_PRE_SAFE_RECORDER_2_GetErrorStatus: operation=NvMService_NVP_BLOCK_ID_PRE_SAFE_RECORDER_2.GetErrorStatus
            SC_NvMService_NVP_BLOCK_ID_PRE_SAFE_RECORDER_2_ReadBlock: operation=NvMService_NVP_BLOCK_ID_PRE_SAFE_RECORDER_2.ReadBlock
            SC_NvMService_NVP_BLOCK_ID_PRE_SAFE_RECORDER_2_WriteBlock: operation=NvMService_NVP_BLOCK_ID_PRE_SAFE_RECORDER_2.WriteBlock
        DIA_runDid0242_PRE_SAFE_Recorder_2_ReadData
        DIA_runDid0242_PRE_SAFE_Recorder_2_ReadDataLength
        DIA_runDid0242_PRE_SAFE_Recorder_2_WriteData
          sync call SC_NvMService_NVP_BLOCK_ID_PRE_SAFE_RECORDER_2_SetRamBlockStatus: operation=NvMService_NVP_BLOCK_ID_PRE_SAFE_RECORDER_2.SetRamBlockStatus
        DIA_runDid0200_CAN_input_Read_Neues_Bitfeld_1_ConditionCheckRead
        DIA_runDid0200_CAN_input_Read_Neues_Bitfeld_1_ReadData
          data-receive-point-by-arguments:
            access REC_IG_Ign_Stat_Pr5_ST3_46s203zrl2qg54zbkbmirlx2b_Ign_Stat_Pr5_ST3: accessed-variable=IG_Ign_Stat_Pr5_ST3_46s203zrl2qg54zbkbmirlx2b.Ign_Stat_Pr5_ST3
            access REC_IF_DidA_ExtTest_Pres_ST3_DidA_ExtTest_Pres_ST3: accessed-variable=IF_DidA_ExtTest_Pres_ST3.DidA_ExtTest_Pres_ST3
            access REC_IG_Bckl_Sw_Fx_Stat_Pr5_ST3_6ckxfn8j26ez9slws8s7zuact_Bckl_Sw_Fx_Stat_Pr5_ST3: accessed-variable=IG_Bckl_Sw_Fx_Stat_Pr5_ST3_6ckxfn8j26ez9slws8s7zuact.Bckl_Sw_Fx_Stat_Pr5_ST3
        DIA_runDid0200_CAN_input_Read_Neues_Bitfeld_2_ConditionCheckRead
        DIA_runDid0200_CAN_input_Read_Neues_Bitfeld_2_ReadData
          data-receive-point-by-arguments:
            access REC_IG_PresfAct_Adj_Pr5_ST3_863uuptg5wch3t7i31c8crpa2_PresfAct_Adj_Pr5_ST3: accessed-variable=IG_PresfAct_Adj_Pr5_ST3_863uuptg5wch3t7i31c8crpa2.PresfAct_Adj_Pr5_ST3
        DIA_runDid0200_CAN_input_Read_Neues_Bitfeld_3_ReadData
          data-receive-point-by-arguments:
            access REC_IF_BeltHdOvr_XX_Stat_ST3_BeltHdOvr_XX_Stat_ST3: accessed-variable=IF_BeltHdOvr_XX_Stat_ST3.BeltHdOvr_XX_Stat_ST3
            access REC_IG_PT4_PTCoor4_Pr5_ST3_3rxtipq9xm5agzf69e8usehmj_PT4_PTCoor4_Pr5_ST3: accessed-variable=IG_PT4_PTCoor4_Pr5_ST3_3rxtipq9xm5agzf69e8usehmj.PT4_PTCoor4_Pr5_ST3
        DIA_runDid0200_CAN_input_Read_Neues_Bitfeld_4_ReadData
          data-receive-point-by-arguments:
            access REC_IG_ORC_Impact3_Pr5_ST3_35qgq57bw73eamvx4gelk7iiv_ORC_Impact3_Pr5_ST3: accessed-variable=IG_ORC_Impact3_Pr5_ST3_35qgq57bw73eamvx4gelk7iiv.ORC_Impact3_Pr5_ST3
            access REC_IF_PN14_SupBat_Volt_ST3_PN14_SupBat_Volt_ST3: accessed-variable=IF_PN14_SupBat_Volt_ST3.PN14_SupBat_Volt_ST3
        DIA_runDid0200_CAN_input_Read_Neues_Bitfeld_5_ReadData
          data-receive-point-by-arguments:
            access REC_IF_PN14_DDP_Sw_Stat_ST3_PN14_DDP_Sw_Stat_ST3: accessed-variable=IF_PN14_DDP_Sw_Stat_ST3.PN14_DDP_Sw_Stat_ST3
            access REC_IF_PN14_ProdMd_Stat_ST3_PN14_ProdMd_Stat_ST3: accessed-variable=IF_PN14_ProdMd_Stat_ST3.PN14_ProdMd_Stat_ST3
            access REC_IF_PN14_TransMd_Stat_ST3_PN14_TransMd_Stat_ST3: accessed-variable=IF_PN14_TransMd_Stat_ST3.PN14_TransMd_Stat_ST3
        DIA_runDid0200_CAN_input_Read_Neues_Bitfeld_6_ReadData
          data-receive-point-by-arguments:
            5 x access:
              REC_IF_PN14_SupBat_Volt_ST3_PN14_SupBat_Volt_ST3: accessed-variable=IF_PN14_SupBat_Volt_ST3.PN14_SupBat_Volt_ST3
              REC_IG_PT4_PTCoor4_Pr5_ST3_3rxtipq9xm5agzf69e8usehmj_PT4_PTCoor4_Pr5_ST3: accessed-variable=IG_PT4_PTCoor4_Pr5_ST3_3rxtipq9xm5agzf69e8usehmj.PT4_PTCoor4_Pr5_ST3
              REC_IG_PT4_PTCoor_DrvPosn_Gear_Pr5_ST3_c8lirmw9wm5odas0h648yyd4w_PT4_PTCoor_DrvPosn_Gear_Pr5_ST3: accessed-variable=IG_PT4_PTCoor_DrvPosn_Gear_Pr5_ST3_c8lirmw9wm5odas0h648yyd4w.PT4_PTCoor_DrvPosn_Gear_Pr5_ST3
              REC_IG_EVC_CfgList_01_08_Pr5_ST3_40zxqtxkwyhasb66rr3qexjf2_EVC_CfgList_01_08_Pr5_ST3: accessed-variable=IG_EVC_CfgList_01_08_Pr5_ST3_40zxqtxkwyhasb66rr3qexjf2.EVC_CfgList_01_08_Pr5_ST3
              REC_R_BltSlckDec_Md_Rq_HU_ST3_BltSlckDec_Md_Rq_HU_ST3: accessed-variable=R_BltSlckDec_Md_Rq_HU_ST3.BltSlckDec_Md_Rq_HU_ST3
        DIA_runDid0200_CAN_input_Read_Supply_battery_voltage_ReadData
          data-receive-point-by-arguments:
            access REC_IF_PN14_SupBat_Volt_ST3_PN14_SupBat_Volt_ST3: accessed-variable=IF_PN14_SupBat_Volt_ST3.PN14_SupBat_Volt_ST3
        DIA_runDid0200_CAN_input_Read_Neues_Bitfeld_7_ReadData
          data-receive-point-by-arguments:
            access REC_IG_SBeltTens_SP_Lvl_Pr5_ST3_aljrkz9re372o0jtum2i5lh8w_SBeltTens_SP_Lvl_Pr5_ST3: accessed-variable=IG_SBeltTens_SP_Lvl_Pr5_ST3_aljrkz9re372o0jtum2i5lh8w.SBeltTens_SP_Lvl_Pr5_ST3
            access REC_prrExtTestPres_b8ExtTesterPresent: accessed-variable=prrExtTestPres.b8ExtTesterPresent
            access REC_prrDTCConfirmed_b8DTCConfirmed: accessed-variable=prrDTCConfirmed.b8DTCConfirmed
        DIA_runDid0200_CAN_input_Read_Neues_Bitfeld_8_ReadData
          data-receive-point-by-arguments:
            access REC_IG_SBeltTens_SP_Lvl_Pr5_ST3_aljrkz9re372o0jtum2i5lh8w_SBeltTens_SP_Lvl_Pr5_ST3: accessed-variable=IG_SBeltTens_SP_Lvl_Pr5_ST3_aljrkz9re372o0jtum2i5lh8w.SBeltTens_SP_Lvl_Pr5_ST3
        DIA_runDid0200_CAN_input_Read_Neues_Bitfeld_{3..8}_ConditionCheckRead
        DIA_runDid0200_CAN_input_Read_Supply_battery_voltage_ConditionCheckRead
        DIA_runDidFD01_SWVersionRead
        DIA_runDidFD01_SWVersionConditionCheckRead
        DIA_runDid00140_Obsolescence_Data_BSR_Current_Value_Read
        DIA_runDid00140_Obsolescence_Data_BSR_Threshold_Green_To_Yellow_Read
        DIA_runDid00140_Obsolescence_Data_BSR_Threshold_Yellow_To_Red_Read
        DIA_runDid00140_Obsolescence_Data_Haptic_Warning_Current_Value_Read
        DIA_runDid00140_Obsolescence_Data_Haptic_Warning_Treshold_Green_To_Yellow_Read
        DIA_runDid00140_Obsolescence_Data_Haptic_Warning_Treshold_Yellow_To_Red_Read
        DIA_runDid00140_Obsolescence_Data_PRE_CRASH_Current_Value_Read
        DIA_runDid00140_Obsolescence_Data_PRE_CRASH_Treshold_Green_To_Yellow_Read
        DIA_runDid00140_Obsolescence_Data_PRE_CRASH_Treshold_Yellow_To_Red_Read
        DIA_runDid00140_Obsolescence_Data_PRE_SAFE_Lvl_4_5_Current_Value_Read
        DIA_runDid00140_Obsolescence_Data_PRE_SAFE_Lvl_4_5_Treshold_Green_To_Yellow_Read
        DIA_runDid00140_Obsolescence_Data_PRE_SAFE_Lvl_4_5_Treshold_Yellow_To_Red_Read
        DIA_runDid00140_Obsolescence_Data_BSR_Current_Value_ConditionCheckRead
          sync call SC_If_Obsolescence_Data_Get_Data: operation=If_Obsolescence_Data.Get_Data
        DIA_runDid00140_Obsolescence_Data_BSR_Threshold_Green_To_Yellow_ConditionCheckRead
        DIA_runDid00140_Obsolescence_Data_BSR_Threshold_Yellow_To_Red_ConditionCheckRead
        DIA_runDid00140_Obsolescence_Data_Haptic_Warning_Current_Value_ConditionCheckRead
        DIA_runDid00140_Obsolescence_Data_Haptic_Warning_Treshold_Green_To_Yellow_ConditionCheckRead
        DIA_runDid00140_Obsolescence_Data_Haptic_Warning_Treshold_Yellow_To_Red_ConditionCheckRead
        DIA_runDid00140_Obsolescence_Data_PRE_CRASH_Current_Value_ConditionCheckRead
        DIA_runDid00140_Obsolescence_Data_PRE_CRASH_Treshold_Green_To_Yellow_ConditionCheckRead
        DIA_runDid00140_Obsolescence_Data_PRE_CRASH_Treshold_Yellow_To_Red_ConditionCheckRead
        DIA_runDid00140_Obsolescence_Data_PRE_SAFE_Lvl_4_5_Current_Value_ConditionCheckRead
        DIA_runDid00140_Obsolescence_Data_PRE_SAFE_Lvl_4_5_Treshold_Green_To_Yellow_ConditionCheckRead
        DIA_runDid00140_Obsolescence_Data_PRE_SAFE_Lvl_4_5_Treshold_Yellow_To_Red_ConditionCheckRead
        DIA_runDidFD50_Hardware_Version_Information_Write_HW_patch_level
        DIA_runDidFD50_Hardware_Version_Information_Write_HW_week
        DIA_runDidFD50_Hardware_Version_Information_Write_HW_year
          sync call SC_NvMService_NVP_BLOCK_ID_HW_VERSION_WriteBlock: operation=NvMService_NVP_BLOCK_ID_HW_VERSION.WriteBlock
          sync call SC_NvMService_NVP_BLOCK_ID_HW_VERSION_GetErrorStatus: operation=NvMService_NVP_BLOCK_ID_HW_VERSION.GetErrorStatus
          sync call SC_NvMService_NVP_BLOCK_ID_HW_VERSION_SetRamBlockStatus: operation=NvMService_NVP_BLOCK_ID_HW_VERSION.SetRamBlockStatus
        DIA_runDid0210_CAN_output_Read_CANoutput1_ConditionCheckRead
        DIA_runDid0210_CAN_output_Read_CANoutput1_ReadData
          data-receive-point-by-arguments:
            access REC_IF_RBTM_FL_Disp_Rq_ST3_RBTM_FL_Disp_Rq_ST3: accessed-variable=IF_RBTM_FL_Disp_Rq_ST3.RBTM_FL_Disp_Rq_ST3
            access REC_IF_RBTM_FR_Disp_Rq_ST3_RBTM_FR_Disp_Rq_ST3: accessed-variable=IF_RBTM_FR_Disp_Rq_ST3.RBTM_FR_Disp_Rq_ST3
            access REC_IF_BltSlckDec_Md_XX_Stat_ST3_BltSlckDec_Md_XX_Stat_ST3: accessed-variable=IF_BltSlckDec_Md_XX_Stat_ST3.BltSlckDec_Md_XX_Stat_ST3
        DIA_runDid0210_CAN_output_Read_PS_Curve_XX_Stat_ST3_ConditionCheckRead
        DIA_runDid0210_CAN_output_Read_PS_Curve_XX_Stat_ST3_ReadData
          data-receive-point-by-arguments:
            access REC_IF_PS_Curve_FL_Stat_ST3_PS_Curve_FL_Stat_ST3: accessed-variable=IF_PS_Curve_FL_Stat_ST3.PS_Curve_FL_Stat_ST3
            access REC_IF_PS_Curve_FR_Stat_ST3_PS_Curve_FR_Stat_ST3: accessed-variable=IF_PS_Curve_FR_Stat_ST3.PS_Curve_FR_Stat_ST3
        DIA_runDid0210_CAN_output_Read_RBTMxx_Actv_Lvl_ST35_ConditionCheckRead
        DIA_runDid0210_CAN_output_Read_RBTMxx_Actv_Lvl_ST35_ReadData
          data-receive-point-by-arguments:
            access REC_IF_RBTMFL_Actv_Lvl_ST35_RBTMFL_Actv_Lvl_ST35: accessed-variable=IF_RBTMFL_Actv_Lvl_ST35.RBTMFL_Actv_Lvl_ST35
            access REC_IF_RBTMFR_Actv_Lvl_ST35_RBTMFR_Actv_Lvl_ST35: accessed-variable=IF_RBTMFR_Actv_Lvl_ST35.RBTMFR_Actv_Lvl_ST35
        DIA_runDid0210_CAN_output_Read_RBTMxx_SP_ActvClient_ST35_ConditionCheckRead
        DIA_runDid0210_CAN_output_Read_RBTMxx_SP_ActvClient_ST35_ReadData
          data-receive-point-by-arguments:
            access REC_IF_RBTMFL_SP_ActvClient_ST35_RBTMFL_SP_ActvClient_ST35: accessed-variable=IF_RBTMFL_SP_ActvClient_ST35.RBTMFL_SP_ActvClient_ST35
            access REC_IF_RBTMFR_SP_ActvClient_ST35_RBTMFR_SP_ActvClient_ST35: accessed-variable=IF_RBTMFR_SP_ActvClient_ST35.RBTMFR_SP_ActvClient_ST35
        DIA_runDid0210_CAN_output_Read_RBTMxx_SP_FctPrecond_Stat_ST35_ConditionCheckRead
        DIA_runDid0210_CAN_output_Read_RBTMxx_SP_FctPrecond_Stat_ST35_ReadData
          data-receive-point-by-arguments:
            access REC_IF_RBTMFL_SP_FctPrecond_Stat_ST35_RBTMFL_SP_FctPrecond_Stat_ST35: accessed-variable=IF_RBTMFL_SP_FctPrecond_Stat_ST35.RBTMFL_SP_FctPrecond_Stat_ST35
            access REC_IF_RBTMFR_SP_FctPrecond_Stat_ST35_RBTMFR_SP_FctPrecond_Stat_ST35: accessed-variable=IF_RBTMFR_SP_FctPrecond_Stat_ST35.RBTMFR_SP_FctPrecond_Stat_ST35
        DIA_runDid0220_HW_input_Read_Voltage_KL30t_ConditionCheckRead
        DIA_runDid0220_HW_input_Read_Voltage_KL30t_ReadData
          sync call SC_pseKL30_V_Get: operation=pclKL30_V.Get
        DIA_runDid0240_Internal_ECU_information_Read_Autosar_System_State_EcuM_State_ConditionCheckRead
        DIA_runDid0240_Internal_ECU_information_Read_Autosar_System_State_EcuM_State_ReadData: mode-access-point=EcuM_CurrentMode.currentMode
        DIA_runDid0220_HW_input_Read_Voltage_Motor_ConditionCheckRead
        DIA_runDid0220_HW_input_Read_Voltage_Motor_ReadData
          sync call SC_pseMotor_Vp_Get: operation=pclMotor_Vp.Get
        DIA_runDid0240_Internal_ECU_information_Read_ECU_Temperature_ConditionCheckRead
        DIA_runDid0240_Internal_ECU_information_Read_ECU_Temperature_ReadData
          sync call SC_pseECUT_T_GetFiltered_deg: operation=pclECUT_T.GetFiltered_deg
        DIA_runDid0240_Internal_ECU_information_Read_MOTOR_Current_ReadData
          sync call SC_psvMotor_I_Get_A: operation=pclMotor_I.Get_A
        DIA_runDid0240_Internal_ECU_information_Read_MOTOR_Current_ConditionCheckRead
          sync call SC_pclMotor_I_Get_mA: operation=pclMotor_I.Get_mA
        DIA_runDidFD03_ECUTraceabilityNumberRead
        DIA_runDidFD03_ECUTraceabilityNumberWrite
          sync call SC_NvMService_NVP_BLOCK_ID_AEE_TRACEABILITY_WriteBlock: operation=NvMService_NVP_BLOCK_ID_AEE_TRACEABILITY.WriteBlock
          sync call SC_NvMService_NVP_BLOCK_ID_AEE_TRACEABILITY_GetErrorStatus: operation=NvMService_NVP_BLOCK_ID_AEE_TRACEABILITY.GetErrorStatus
        DIA_runDidFD03_PCBAProgrammedPartNumberConditionCheckRead
        DIA_runDidFD03_PCBAProgrammedPartNumberWrite
          sync call SC_NvMService_NVP_BLOCK_ID_PCBA_PPN_GetErrorStatus: operation=NvMService_NVP_BLOCK_ID_PCBA_PPN.GetErrorStatus
          sync call SC_NvMService_NVP_BLOCK_ID_PCBA_PPN_SetRamBlockStatus: operation=NvMService_NVP_BLOCK_ID_PCBA_PPN.SetRamBlockStatus
          sync call SC_NvMService_NVP_BLOCK_ID_PCBA_PPN_WriteBlock: operation=NvMService_NVP_BLOCK_ID_PCBA_PPN.WriteBlock
        DIA_runDidFD03_PCBAProgrammedPartNumberRead
        DIA_runDidFD03_ECUTraceabilityNumberConditionCheckRead
        DIA_runRid0203_CheckProgrammingPreconditionsStart
        DIA_runDidFD30_Temperature_Sensor_Calibration_Point_Read_Offset_Point_ReadData
        DIA_runDidFD30_Temperature_Sensor_Calibration_Point_Read_Offset_Point_ConditionCheckRead
        DIA_runDidFD30_Temperature_Sensor_Calibration_Point_Read_Offset_Point_WriteData
          sync call SC_NvMService_NVP_BLOCK_TEMP_SENSOR_TABLE_WriteBlock: operation=NvMService_NVP_BLOCK_TEMP_SENSOR_TABLE.WriteBlock
          sync call SC_NvMService_NVP_BLOCK_TEMP_SENSOR_TABLE_GetErrorStatus: operation=NvMService_NVP_BLOCK_TEMP_SENSOR_TABLE.GetErrorStatus
          sync call SC_NvMService_NVP_BLOCK_TEMP_SENSOR_TABLE_SetRamBlockStatus: operation=NvMService_NVP_BLOCK_TEMP_SENSOR_TABLE.SetRamBlockStatus
        DIA_runDidFDDF_Velocity_PI_Regulation_Coefficient_Read_Input_Velocity_Coefficient_ConditionCheckRead
        DIA_runDidFDDF_Velocity_PI_Regulation_Coefficient_Read_Input_Velocity_Coefficient_ReadData
        DIA_runDidFDDF_Velocity_PI_Regulation_Coefficient_Read_Input_Velocity_Coefficient_WriteData
          sync call SC_NvMService_NVP_BLOCK_ID_VELOCITY_PID_PARAM_GetErrorStatus: operation=NvMService_NVP_BLOCK_ID_VELOCITY_PID_PARAM.GetErrorStatus
          sync call SC_NvMService_NVP_BLOCK_ID_VELOCITY_PID_PARAM_SetRamBlockStatus: operation=NvMService_NVP_BLOCK_ID_VELOCITY_PID_PARAM.SetRamBlockStatus
          sync call SC_NvMService_NVP_BLOCK_ID_VELOCITY_PID_PARAM_WriteBlock: operation=NvMService_NVP_BLOCK_ID_VELOCITY_PID_PARAM.WriteBlock
  swc implementation DIA_AC_DiagOnCAN_Implementation: behavior=DIA_IB_DiagOnCAN
